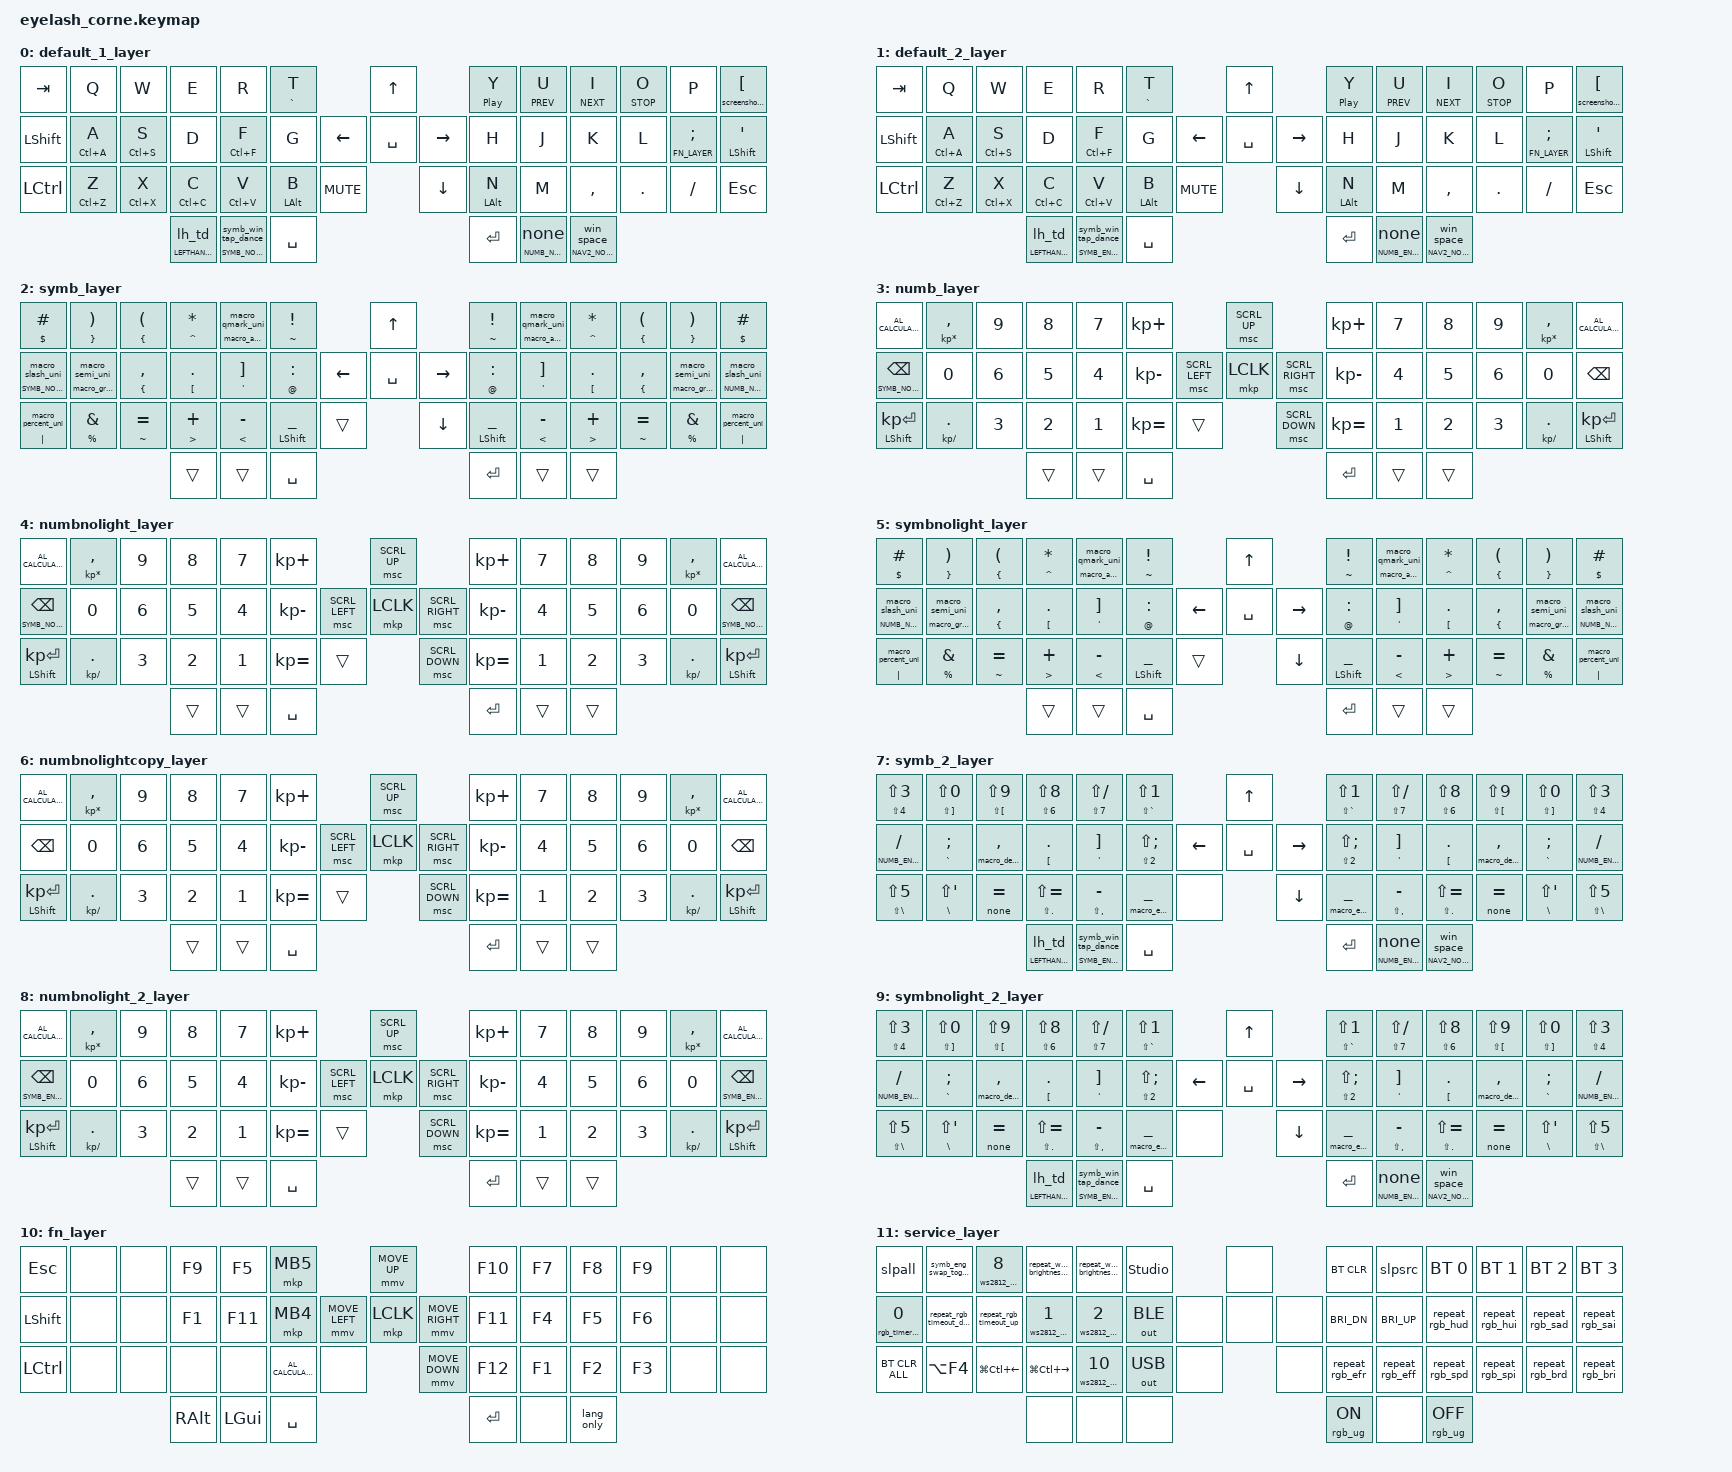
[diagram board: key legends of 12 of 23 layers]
#define ZMK_POINTING_DEFAULT_MOVE_VAL 1200
#define ZMK_POINTING_DEFAULT_SCRL_VAL 25
#include <input/processors.dtsi>
#include <zephyr/dt-bindings/input/input-event-codes.h>
#include <behaviors.dtsi>
#include <behaviors/ws2812_widget.dtsi>
#include <behaviors/ws2812_layer_sync.dtsi>
#include <behaviors/ws2812_activity_sync.dtsi>
#include <dt-bindings/zmk/bt.h>
#include <dt-bindings/zmk/keys.h>
#include <dt-bindings/zmk/outputs.h>
#include <dt-bindings/zmk/pointing.h>
#include <dt-bindings/zmk/rgb.h>
#include <behaviors/rgb_timer.dtsi>
#include <behaviors/sleep_source.dtsi>
#include <behaviors/sleep_all.dtsi>

#define BASE_LAYER                    0   // default_layer -> default_1_layer
#define KP_MODE_LAYER                 1   // kp_mode_layer -> default_2_layer
#define SYMB_LAYER                    2
#define NUMB_LAYER                    3
#define NUMB_NOLIGHT_LAYER            4
#define SYMB_NOLIGHT_LAYER            5
#define NUMB_NOLIGHT_COPY_LAYER       6
#define SYMB_ENG_LAYER                7   // symb_layer_eng -> symb_2_layer
#define NUMB_ENG_NOLIGHT_LAYER        8   // numbnolight_eng_layer -> numbnolight_2_layer
#define SYMB_ENG_NOLIGHT_LAYER        9   // symbnolight_eng_layer -> symbnolight_2_layer
#define FN_LAYER                      10
#define SERVICE_LAYER                 11
#define NAV1_LAYER                    12  // nav1_layer    -> nav_1_layer
#define NAV2_LAYER                    13  // nav2_layer    -> nav_2_layer
#define NAV2_NOLIGHT_LAYER            14
#define NAV3_LAYER                    15  // nav3_layer    -> nav_3_layer
#define GAMING1_LAYER                 16  // gaming1_layer -> gaming_1_layer
#define GAMING2_LAYER                 17  // gaming2_layer -> gaming_2_layer
#define GAMING3_LAYER                 18  // gaming3_layer -> gaming_3_layer
#define SPEEDTYPE_LAYER               19  // speedtype     -> speedtype_layer
#define LEFTHAND_LAYER                20
#define LEFTHAND_NOLIGHT_LAYER        21
#define NUMB_ENG_NOLIGHT_COPY_LAYER   22  // numbnolight_eng_copy_layer -> numbnolight_copy_2_layer

// --- НАСТРОЙКИ ОБОРУДОВАНИЯ И ПЕРИФЕРИИ ---
// Количество адресных светодиодов WS2812 на одной половине сплит-клавиатуры
&led_strip {
	chain-length = <21>;
};

// Базовые параметры скорости перемещения курсора мыши и скролла:
// Увеличение чувствительности курсора (x2) и стандартный скролл (x1)
&mmv_input_listener { input-processors = <&zip_xy_scaler 2 1>; };
&msc_input_listener { input-processors = <&zip_scroll_scaler 1 1>; };

// Настройки поведения прокрутки мыши (колесо):
// Мгновенный отклик, нулевая задержка и отсутствие кривой ускорения
&msc {
	acceleration-exponent = <0>;
	time-to-max-speed-ms = <0>;
	delay-ms = <0>;
};

// Настройки поведения курсора мыши (эмуляция перемещения указателя):
// Плавный разгон до максимальной скорости за 500 мс, линейное ускорение;
// trigger-period-ms = 16 задаёт период повторной генерации движения.
&mmv {
	time-to-max-speed-ms = <500>;
	acceleration-exponent = <1>;
	trigger-period-ms = <16>;
};

/ {
	chosen {
		zmk,ws2812-widget = &led_strip;
	};

	// Soft Off: разрешить пробуждение любой клавишей матрицы.
	// kscan0 уже имеет wakeup-source в eyelash_corne.dtsi.
	soft_off_wakers {
		compatible = "zmk,soft-off-wakeup-sources";
		wakeup-sources = <&kscan0>;
	};

	// --- ПОВЕДЕНИЯ КЛАВИШ (BEHAVIORS) ---
	behaviors {
		// ============================================================
		// CAPS LOCK + ИНДИКАЦИЯ НА LED 5,6 (БЕЗ СЛОЯ-ФЛАГА)
		// ============================================================
		// caps_toggle отправляет обычный HID Caps Lock (&kp CAPS).
		// Сам keymap не хранит отдельный слой/флаг для состояния Caps.
		//
		// На левой половине widget.c, при CONFIG_ZMK_HID_INDICATORS=y,
		// слушает событие zmk_hid_indicators_changed и берёт РЕАЛЬНОЕ состояние Caps Lock из HID-indicator report хоста.
		//
		// Поэтому двойное срабатывание R+T через combo_rt_caps_td
		// переключает Caps, а LED 5,6 отражают подтверждённое хостом состояние.
		// ============================================================

		// Макрос отправки Caps Lock. Подсветкой непосредственно он не управляет.
		caps_toggle: caps_toggle {
			compatible = "zmk,behavior-macro";
			#binding-cells = <0>;
			wait-ms = <20>;   // Параметр задержки между действиями макроса
			tap-ms = <20>;    // Длительность tap-события макроса
			bindings = <&kp CAPS>;
		};

		// ============================================================
		// МАКРОСЫ ws2812_eff_*
		// ============================================================
		// Справка по параметрам текущего zmk-ws2812-driver/main:
		//   0 = ручная индикация слоя;
		//   1 = индикация батареи локальной половины;
		//   2 = переключение временных WS2812-индикаций;
		//   3 = включение временных индикаций;
		//   4 = выключение временных индикаций;
		//   5 = индикация батареи обеих половин;
		//   6 = уменьшение яркости виджетов WS2812 на 10%;
		//   7 = увеличение яркости виджетов WS2812 на 10%;
		//   8 = сброс яркости виджетов WS2812 на 50%;
		//   9 = оранжевая индикация слоя.
		// ============================================================

		// Историческое имя "next" сохранено; &ws2812_wdg 6 уменьшает яркость виджетов.
		ws2812_eff_next: ws2812_eff_next {
			compatible = "zmk,behavior-macro";
			#binding-cells = <0>;
			wait-ms = <0>;
			tap-ms = <0>;
			bindings = <&ws2812_wdg 6>;
		};

		// Историческое имя "prev" сохранено; &ws2812_wdg 7 увеличивает яркость виджетов.
		ws2812_eff_prev: ws2812_eff_prev {
			compatible = "zmk,behavior-macro";
			#binding-cells = <0>;
			wait-ms = <0>;
			tap-ms = <0>;
			bindings = <&ws2812_wdg 7>;
		};

		// Историческое имя "off" сохранено; &ws2812_wdg 8 сбрасывает яркость виджетов на 50%.
		ws2812_eff_off: ws2812_eff_off {
			compatible = "zmk,behavior-macro";
			#binding-cells = <0>;
			wait-ms = <0>;
			tap-ms = <0>;
			bindings = <&ws2812_wdg 8>;
		};

		// Переименовано, чтобы не конфликтовать с возможным rgb_timer из include.
		rgb_timer_custom: rgbtimer_custom {
			compatible = "zmk,behavior-rgb-timer";
			#binding-cells = <1>;
		};

		rgb_timeout_up: rgb_timeout_up {
			compatible = "zmk,behavior-rgb-timeout";
			#binding-cells = <1>;
		};

		rgb_timeout_down: rgb_timeout_down {
			compatible = "zmk,behavior-rgb-timeout";
			#binding-cells = <1>;
		};

		// Автоповтор: действие сразу, повтор через 450 мс, затем каждые 200 мс.
		repeat_rgb_hud: repeat_rgb_hud {
			compatible = "zmk,behavior-auto-repeat";
			#binding-cells = <0>;
			bindings = <&rgb_ug RGB_HUD>;
			delay-ms = <450>;
			interval-ms = <200>;
		};

		// Автоповтор: действие сразу, повтор через 450 мс, затем каждые 200 мс.
		repeat_rgb_hui: repeat_rgb_hui {
			compatible = "zmk,behavior-auto-repeat";
			#binding-cells = <0>;
			bindings = <&rgb_ug RGB_HUI>;
			delay-ms = <450>;
			interval-ms = <200>;
		};

		// Автоповтор: действие сразу, повтор через 450 мс, затем каждые 200 мс.
		repeat_rgb_sad: repeat_rgb_sad {
			compatible = "zmk,behavior-auto-repeat";
			#binding-cells = <0>;
			bindings = <&rgb_ug RGB_SAD>;
			delay-ms = <450>;
			interval-ms = <200>;
		};

		// Автоповтор: действие сразу, повтор через 450 мс, затем каждые 200 мс.
		repeat_rgb_sai: repeat_rgb_sai {
			compatible = "zmk,behavior-auto-repeat";
			#binding-cells = <0>;
			bindings = <&rgb_ug RGB_SAI>;
			delay-ms = <450>;
			interval-ms = <200>;
		};

		// Автоповтор: действие сразу, повтор через 450 мс, затем каждые 200 мс.
		repeat_rgb_spd: repeat_rgb_spd {
			compatible = "zmk,behavior-auto-repeat";
			#binding-cells = <0>;
			bindings = <&rgb_ug RGB_SPD>;
			delay-ms = <450>;
			interval-ms = <200>;
		};

		// Автоповтор: действие сразу, повтор через 450 мс, затем каждые 200 мс.
		repeat_rgb_spi: repeat_rgb_spi {
			compatible = "zmk,behavior-auto-repeat";
			#binding-cells = <0>;
			bindings = <&rgb_ug RGB_SPI>;
			delay-ms = <450>;
			interval-ms = <200>;
		};

		// Автоповтор: действие сразу, повтор через 450 мс, затем каждые 200 мс.
		repeat_rgb_brd: repeat_rgb_brd {
			compatible = "zmk,behavior-auto-repeat";
			#binding-cells = <0>;
			bindings = <&rgb_ug RGB_BRD>;
			delay-ms = <450>;
			interval-ms = <200>;
		};

		// Автоповтор: действие сразу, повтор через 450 мс, затем каждые 200 мс.
		repeat_rgb_bri: repeat_rgb_bri {
			compatible = "zmk,behavior-auto-repeat";
			#binding-cells = <0>;
			bindings = <&rgb_ug RGB_BRI>;
			delay-ms = <450>;
			interval-ms = <200>;
		};
				// Автоповтор переключения на предыдущий RGB-эффект.
		repeat_rgb_efr: repeat_rgb_efr {
			compatible = "zmk,behavior-auto-repeat";
			#binding-cells = <0>;
			bindings = <&rgb_ug RGB_EFR>;
			delay-ms = <450>;
			interval-ms = <200>;
		};

		// Автоповтор переключения на следующий RGB-эффект.
		repeat_rgb_eff: repeat_rgb_eff {
			compatible = "zmk,behavior-auto-repeat";
			#binding-cells = <0>;
			bindings = <&rgb_ug RGB_EFF>;
			delay-ms = <450>;
			interval-ms = <200>;
		};

		// Автоповтор: действие сразу, повтор через 450 мс, затем каждые 200 мс.
		repeat_rgb_timeout_down: repeat_rgb_timeout_down {
			compatible = "zmk,behavior-auto-repeat";
			#binding-cells = <0>;
			bindings = <&rgb_timer_custom 2>;
			delay-ms = <450>;
			interval-ms = <200>;
		};

		// Автоповтор: действие сразу, повтор через 450 мс, затем каждые 200 мс.
		repeat_rgb_timeout_up: repeat_rgb_timeout_up {
			compatible = "zmk,behavior-auto-repeat";
			#binding-cells = <0>;
			bindings = <&rgb_timer_custom 1>;
			delay-ms = <450>;
			interval-ms = <200>;
		};

		// Автоповтор: действие сразу, повтор через 450 мс, затем каждые 200 мс.
		repeat_ws2812_brightness_down: repeat_ws2812_brightness_down {
			compatible = "zmk,behavior-auto-repeat";
			#binding-cells = <0>;
			bindings = <&ws2812_wdg 6>;
			delay-ms = <450>;
			interval-ms = <200>;
		};

		// Автоповтор: действие сразу, повтор через 450 мс, затем каждые 200 мс.
		repeat_ws2812_brightness_up: repeat_ws2812_brightness_up {
			compatible = "zmk,behavior-auto-repeat";
			#binding-cells = <0>;
			bindings = <&ws2812_wdg 7>;
			delay-ms = <450>;
			interval-ms = <200>;
		};

		// Вспомогательный макрос для одиночного срабатывания комбо R+T:
		// Быстро отправляет буквы R и T подряд без задержки
		macro_combo_rt: macro_combo_rt {
			compatible = "zmk,behavior-macro";
			#binding-cells = <0>;
			wait-ms = <0>;
			tap-ms = <0>;
			bindings = <&macro_tap &kp R>, <&macro_tap &kp T>;
		};

		// Tap Dance для комбо R+T:
		// 1 одновременное нажатие = вывод макроса R+T (просто буквы)
		// 2 одновременных нажатия (окно 450 мс) = переключение Caps + подсветка
		combo_rt_caps_td: combo_rt_caps_td {
			compatible = "zmk,behavior-tap-dance";
			#binding-cells = <0>;
			tapping-term-ms = <450>;
			bindings = <&macro_combo_rt>, <&caps_toggle>;
		};

		// ============================================================
		// КОНЕЦ БЛОКА CAPS LOCK ПОДСВЕТКИ
		// ============================================================

		// Макрос для точки через Alt+Code (046 на NumPad = точка)
		macro_dot_uni: macro_dot_uni {
			compatible = "zmk,behavior-macro";
			#binding-cells = <0>;
			wait-ms = <5>;
			tap-ms = <5>;
			bindings =
				<&macro_press &kp LALT>,
				<&macro_tap &kp KP_N0>,
				<&macro_tap &kp KP_N4>,
				<&macro_tap &kp KP_N6>,
				<&macro_release &kp LALT>;
		};

		// Макрос для запятой через Alt+Code (044 на NumPad = запятая)
		macro_comma_uni: macro_comma_uni {
			compatible = "zmk,behavior-macro";
			#binding-cells = <0>;
			wait-ms = <5>;
			tap-ms = <5>;
			bindings =
				<&macro_press &kp LALT>,
				<&macro_tap &kp KP_N0>,
				<&macro_tap &kp KP_N4>,
				<&macro_tap &kp KP_N4>,
				<&macro_release &kp LALT>;
		};

		// Знак вопроса через Alt+Code (063 на NumPad = ?)
		macro_qmark_uni: macro_qmark_uni {
			compatible = "zmk,behavior-macro";
			#binding-cells = <0>;
			wait-ms = <5>;
			tap-ms = <5>;
			bindings =
				<&macro_press &kp LALT>,
				<&macro_tap &kp KP_N0>,
				<&macro_tap &kp KP_N6>,
				<&macro_tap &kp KP_N3>,
				<&macro_release &kp LALT>;
		};

		// Двоеточие через Alt+Code (058 на NumPad = :)
		macro_colon_uni: macro_colon_uni {
			compatible = "zmk,behavior-macro";
			#binding-cells = <0>;
			wait-ms = <5>;
			tap-ms = <5>;
			bindings =
				<&macro_press &kp LALT>,
				<&macro_tap &kp KP_N0>,
				<&macro_tap &kp KP_N5>,
				<&macro_tap &kp KP_N8>,
				<&macro_release &kp LALT>;
		};

		// Точка с запятой через Alt+Code (059 на NumPad = ;)
		macro_semi_uni: macro_semi_uni {
			compatible = "zmk,behavior-macro";
			#binding-cells = <0>;
			wait-ms = <5>;
			tap-ms = <5>;
			bindings =
				<&macro_press &kp LALT>,
				<&macro_tap &kp KP_N0>,
				<&macro_tap &kp KP_N5>,
				<&macro_tap &kp KP_N9>,
				<&macro_release &kp LALT>;
		};

		// Слэш через Alt+Code (047 на NumPad = /)
		macro_slash_uni: macro_slash_uni {
			compatible = "zmk,behavior-macro";
			#binding-cells = <0>;
			wait-ms = <5>;
			tap-ms = <5>;
			bindings =
				<&macro_press &kp LALT>,
				<&macro_tap &kp KP_N0>,
				<&macro_tap &kp KP_N4>,
				<&macro_tap &kp KP_N7>,
				<&macro_release &kp LALT>;
		};

		// Обратный слэш через Alt+Code (092 на NumPad = \).
		macro_bslh_uni: macro_bslh_uni {
			compatible = "zmk,behavior-macro";
			#binding-cells = <0>;
			wait-ms = <5>;
			tap-ms = <5>;
			bindings =
				<&macro_press &kp LALT>,
				<&macro_tap &kp KP_N0>,
				<&macro_tap &kp KP_N9>,
				<&macro_tap &kp KP_N2>,
				<&macro_release &kp LALT>;
		};

		// @ через Alt+Code (064 = @)
		macro_at_uni: macro_at_uni {
			compatible = "zmk,behavior-macro";
			#binding-cells = <0>;
			wait-ms = <5>;
			tap-ms = <5>;
			bindings =
				<&macro_press &kp LALT>,
				<&macro_tap &kp KP_N0>,
				<&macro_tap &kp KP_N6>,
				<&macro_tap &kp KP_N4>,
				<&macro_release &kp LALT>;
		};

		// ' через Alt+Code (039 = ')
		macro_sqt_uni: macro_sqt_uni {
			compatible = "zmk,behavior-macro";
			#binding-cells = <0>;
			wait-ms = <5>;
			tap-ms = <5>;
			bindings =
				<&macro_press &kp LALT>,
				<&macro_tap &kp KP_N0>,
				<&macro_tap &kp KP_N3>,
				<&macro_tap &kp KP_N9>,
				<&macro_release &kp LALT>;
		};

		// } через Alt+Code (125 = })
		macro_rbrc_uni: macro_rbrc_uni {
			compatible = "zmk,behavior-macro";
			#binding-cells = <0>;
			wait-ms = <5>;
			tap-ms = <5>;
			bindings =
				<&macro_press &kp LALT>,
				<&macro_tap &kp KP_N1>,
				<&macro_tap &kp KP_N2>,
				<&macro_tap &kp KP_N5>,
				<&macro_release &kp LALT>;
		};

		// " однократно (без повтора при удержании)
		macro_dqt_once: macro_dqt_once {
			compatible = "zmk,behavior-macro";
			#binding-cells = <0>;
			wait-ms = <0>;
			tap-ms = <0>;
			bindings =
				<&macro_press &kp DQT>,
				<&macro_release &kp DQT>;
		};

		// Поведение для слоя Lefthand no-light: TAB через Alt+Tab
		alt_tab: alt_tab {
			compatible = "zmk,behavior-macro";
			#binding-cells = <0>;
			wait-ms = <0>;
			tap-ms = <20>;
			bindings =
				<&macro_press &kp LALT>,
				<&macro_tap &kp TAB>,
				<&macro_release &kp LALT>;
		};

		// ~ через Alt+Code (126 = ~)
		macro_tilde_uni: macro_tilde_uni {
			compatible = "zmk,behavior-macro";
			#binding-cells = <0>;
			wait-ms = <5>;
			tap-ms = <5>;
			bindings =
				<&macro_press &kp LALT>,
				<&macro_tap &kp KP_N0>,
				<&macro_tap &kp KP_N1>,
				<&macro_tap &kp KP_N2>,
				<&macro_tap &kp KP_N6>,
				<&macro_release &kp LALT>;
		};

		// | через Alt+Code (124 = |)
		macro_pipe_uni: macro_pipe_uni {
			compatible = "zmk,behavior-macro";
			#binding-cells = <0>;
			wait-ms = <5>;
			tap-ms = <5>;
			bindings =
				<&macro_press &kp LALT>,
				<&macro_tap &kp KP_N0>,
				<&macro_tap &kp KP_N1>,
				<&macro_tap &kp KP_N2>,
				<&macro_tap &kp KP_N4>,
				<&macro_release &kp LALT>;
		};

		// [ через Alt+Code (091 = [)
		macro_lbkt_uni: macro_lbkt_uni {
			compatible = "zmk,behavior-macro";
			#binding-cells = <0>;
			wait-ms = <5>;
			tap-ms = <5>;
			bindings =
				<&macro_press &kp LALT>,
				<&macro_tap &kp KP_N0>,
				<&macro_tap &kp KP_N9>,
				<&macro_tap &kp KP_N1>,
				<&macro_release &kp LALT>;
		};

		// { через Alt+Code (123 = {)
		macro_lbrc_uni: macro_lbrc_uni {
			compatible = "zmk,behavior-macro";
			#binding-cells = <0>;
			wait-ms = <5>;
			tap-ms = <5>;
			bindings =
				<&macro_press &kp LALT>,
				<&macro_tap &kp KP_N1>,
				<&macro_tap &kp KP_N2>,
				<&macro_tap &kp KP_N3>,
				<&macro_release &kp LALT>;
		};

		// $ через Alt+Code (036 = $)
		macro_dollar_uni: macro_dollar_uni {
			compatible = "zmk,behavior-macro";
			#binding-cells = <0>;
			wait-ms = <5>;
			tap-ms = <5>;
			bindings =
				<&macro_press &kp LALT>,
				<&macro_tap &kp KP_N0>,
				<&macro_tap &kp KP_N3>,
				<&macro_tap &kp KP_N6>,
				<&macro_release &kp LALT>;
		};

		// ` через Alt+Code (096 = `)
		macro_grave_uni: macro_grave_uni {
			compatible = "zmk,behavior-macro";
			#binding-cells = <0>;
			wait-ms = <5>;
			tap-ms = <5>;
			bindings =
				<&macro_press &kp LALT>,
				<&macro_tap &kp KP_N0>,
				<&macro_tap &kp KP_N9>,
				<&macro_tap &kp KP_N6>,
				<&macro_release &kp LALT>;
		};

		macro_tilde_direct: macro_tilde_direct {
			compatible = "zmk,behavior-macro";
			#binding-cells = <0>;
			wait-ms = <0>;
			tap-ms = <0>;
			bindings = <&kp LS(GRAVE)>;
		};

		// ° через Alt+Code (0176 = °)
		macro_degree_uni: macro_degree_uni {
			compatible = "zmk,behavior-macro";
			#binding-cells = <0>;
			wait-ms = <5>;
			tap-ms = <5>;
			bindings =
				<&macro_press &kp LALT>,
				<&macro_tap &kp KP_N0>,
				<&macro_tap &kp KP_N1>,
				<&macro_tap &kp KP_N7>,
				<&macro_tap &kp KP_N6>,
				<&macro_release &kp LALT>;
		};

		// — через Alt+Code (0151 = em dash)
		macro_emdash_uni: macro_emdash_uni {
			compatible = "zmk,behavior-macro";
			#binding-cells = <0>;
			wait-ms = <5>;
			tap-ms = <5>;
			bindings =
				<&macro_press &kp LALT>,
				<&macro_tap &kp KP_N0>,
				<&macro_tap &kp KP_N1>,
				<&macro_tap &kp KP_N5>,
				<&macro_tap &kp KP_N1>,
				<&macro_release &kp LALT>;
		};

		// & через Alt+Code (038 = &)
		macro_amp_uni: macro_amp_uni {
			compatible = "zmk,behavior-macro";
			#binding-cells = <0>;
			wait-ms = <5>;
			tap-ms = <5>;
			bindings =
				<&macro_press &kp LALT>,
				<&macro_tap &kp KP_N0>,
				<&macro_tap &kp KP_N3>,
				<&macro_tap &kp KP_N8>,
				<&macro_release &kp LALT>;
		};

		// ^ через Alt+Code (094 = ^)
		macro_caret_uni: macro_caret_uni {
			compatible = "zmk,behavior-macro";
			#binding-cells = <0>;
			wait-ms = <5>;
			tap-ms = <5>;
			bindings =
				<&macro_press &kp LALT>,
				<&macro_tap &kp KP_N0>,
				<&macro_tap &kp KP_N9>,
				<&macro_tap &kp KP_N4>,
				<&macro_release &kp LALT>;
		};

		// < через Alt+Code (060 = <)
		macro_lt_uni: macro_lt_uni {
			compatible = "zmk,behavior-macro";
			#binding-cells = <0>;
			wait-ms = <5>;
			tap-ms = <5>;
			bindings =
				<&macro_press &kp LALT>,
				<&macro_tap &kp KP_N0>,
				<&macro_tap &kp KP_N6>,
				<&macro_tap &kp KP_N0>,
				<&macro_release &kp LALT>;
		};

		// > через Alt+Code (062 = >)
		macro_gt_uni: macro_gt_uni {
			compatible = "zmk,behavior-macro";
			#binding-cells = <0>;
			wait-ms = <5>;
			tap-ms = <5>;
			bindings =
				<&macro_press &kp LALT>,
				<&macro_tap &kp KP_N0>,
				<&macro_tap &kp KP_N6>,
				<&macro_tap &kp KP_N2>,
				<&macro_release &kp LALT>;
		};

		// " через Alt+Code (034 = ")
		macro_dqt_uni: macro_dqt_uni {
			compatible = "zmk,behavior-macro";
			#binding-cells = <0>;
			wait-ms = <5>;
			tap-ms = <5>;
			bindings =
				<&macro_press &kp LALT>,
				<&macro_tap &kp KP_N0>,
				<&macro_tap &kp KP_N3>,
				<&macro_tap &kp KP_N4>,
				<&macro_release &kp LALT>;
		};

		// % через Alt+Code (037 = %)
		macro_percent_uni: macro_percent_uni {
			compatible = "zmk,behavior-macro";
			#binding-cells = <0>;
			wait-ms = <5>;
			tap-ms = <5>;
			bindings =
				<&macro_press &kp LALT>,
				<&macro_tap &kp KP_N0>,
				<&macro_tap &kp KP_N3>,
				<&macro_tap &kp KP_N7>,
				<&macro_release &kp LALT>;
		};

		// Hold-Tap symb_win_td (Левая клавиша большого пальца):
		// Удержание -> слой, переданный первым параметром.
		// В слое 0:      &symb_win_td SYMB_NOLIGHT_LAYER 0
		// В default_2:     &symb_win_td SYMB_ENG_NOLIGHT_LAYER 0
		// В циан-слоях:  &symb_win_td SYMB_ENG_NOLIGHT_LAYER 0
		// Одиночный тап -> ничего (none)
		// Двойной тап (окно 500 мс) -> Win (LGUI) через symb_win_tap_dance
		symb_win_td: symb_win_td {
			compatible = "zmk,behavior-hold-tap";
			#binding-cells = <2>;
			flavor = "tap-preferred";
			tapping-term-ms = <200>;
			quick-tap-ms = <300>;
			bindings = <&mo>, <&symb_win_tap_dance>;
		};

		// Вспомогательный Tap Dance для symb_win_td:
		// 1 тап = none (ничего), 2 тапа (окно 500 мс) = kp LGUI (Win)
		symb_win_tap_dance: symb_win_tap_dance {
			compatible = "zmk,behavior-tap-dance";
			#binding-cells = <0>;
			tapping-term-ms = <500>;
			bindings = <&none>, <&kp LGUI>;
		};

		// Hold-Tap thumb_num_sym_fn:
		// Удержание -> слой, переданный первым параметром.
		// В слое 0:      &thumb_num_sym_fn NUMB_NOLIGHT_LAYER 0
		// В default_2:     &thumb_num_sym_fn NUMB_ENG_NOLIGHT_LAYER 0
		// В циан-слоях:  &thumb_num_sym_fn NUMB_ENG_NOLIGHT_LAYER 0
		// Тап -> &none
		thumb_num_sym_fn: thumb_num_sym_fn {
			compatible = "zmk,behavior-hold-tap";
			#binding-cells = <2>;
			flavor = "tap-preferred";
			tapping-term-ms = <80>;
			bindings = <&mo>, <&none>;
		};

		// Speedtype -> NUMB_ENG_NOLIGHT без перестановки слоёв.
		// SPEEDTYPE_LAYER имеет больший номер, поэтому обычный &mo на нижний цифровой слой
		// был бы перекрыт активным Speedtype. Эти два behavior принудительно выключают/
		// включают SPEEDTYPE_LAYER, не меняя порядок существующих слоёв.
		layer_on: layer_on {
			compatible = "zmk,behavior-toggle-layer";
			#binding-cells = <1>;
			toggle-mode = "on";
		};

		layer_off: layer_off {
			compatible = "zmk,behavior-toggle-layer";
			#binding-cells = <1>;
			toggle-mode = "off";
		};

		// Пока speed_num_hold удерживается:
		// 1) выключаем фиксированный SPEEDTYPE_LAYER;
		// 2) временно включаем существующий NUMB_ENG_NOLIGHT_LAYER;
		// после отпускания выключаем цифры и возвращаем SPEEDTYPE_LAYER.
		speed_num_hold: speed_num_hold {
			compatible = "zmk,behavior-macro";
			#binding-cells = <0>;
			wait-ms = <0>;
			tap-ms = <0>;
			bindings =
				<&macro_tap &layer_off SPEEDTYPE_LAYER>,
				<&macro_press &mo NUMB_ENG_NOLIGHT_LAYER>,
				<&macro_pause_for_release>,
				<&macro_release &mo NUMB_ENG_NOLIGHT_LAYER>,
				<&macro_tap &layer_on SPEEDTYPE_LAYER>;
		};

		// Клавиша после Enter в SPEEDTYPE: tap = ничего, hold = цифровой слой.
		// Тайминг оставлен таким же, как у thumb_num_sym_fn.
		speed_num_ht: speed_num_ht {
			compatible = "zmk,behavior-hold-tap";
			#binding-cells = <2>;
			flavor = "tap-preferred";
			tapping-term-ms = <80>;
			bindings = <&speed_num_hold>, <&none>;
		};

		// Gaming -> NUMB_NOLIGHT_LAYER (Alt-ветка символов).
		// Во всех трёх gaming-слоях клавиша рядом с переключением языка:
		// tap = ничего, hold = NUMB_NOLIGHT_LAYER.
		// GAMING2/GAMING3 работают поверх GAMING1, поэтому для них временно
		// выключаются оба активных gaming-слоя, иначе слой 4 был бы перекрыт.
		gaming1_num_hold: gaming1_num_hold {
			compatible = "zmk,behavior-macro";
			#binding-cells = <0>;
			wait-ms = <0>;
			tap-ms = <0>;
			bindings =
				<&macro_tap &layer_off GAMING1_LAYER>,
				<&macro_press &mo NUMB_NOLIGHT_LAYER>,
				<&macro_pause_for_release>,
				<&macro_release &mo NUMB_NOLIGHT_LAYER>,
				<&macro_tap &layer_on GAMING1_LAYER>;
		};

		gaming1_num_ht: gaming1_num_ht {
			compatible = "zmk,behavior-hold-tap";
			#binding-cells = <2>;
			flavor = "tap-preferred";
			tapping-term-ms = <80>;
			bindings = <&gaming1_num_hold>, <&none>;
		};

		gaming2_num_hold: gaming2_num_hold {
			compatible = "zmk,behavior-macro";
			#binding-cells = <0>;
			wait-ms = <0>;
			tap-ms = <0>;
			bindings =
				<&macro_tap &layer_off GAMING2_LAYER>,
				<&macro_tap &layer_off GAMING1_LAYER>,
				<&macro_press &mo NUMB_NOLIGHT_LAYER>,
				<&macro_pause_for_release>,
				<&macro_release &mo NUMB_NOLIGHT_LAYER>,
				<&macro_tap &layer_on GAMING1_LAYER>,
				<&macro_tap &layer_on GAMING2_LAYER>;
		};

		gaming2_num_ht: gaming2_num_ht {
			compatible = "zmk,behavior-hold-tap";
			#binding-cells = <2>;
			flavor = "tap-preferred";
			tapping-term-ms = <80>;
			bindings = <&gaming2_num_hold>, <&none>;
		};

		gaming3_num_hold: gaming3_num_hold {
			compatible = "zmk,behavior-macro";
			#binding-cells = <0>;
			wait-ms = <0>;
			tap-ms = <0>;
			bindings =
				<&macro_tap &layer_off GAMING3_LAYER>,
				<&macro_tap &layer_off GAMING1_LAYER>,
				<&macro_press &mo NUMB_NOLIGHT_LAYER>,
				<&macro_pause_for_release>,
				<&macro_release &mo NUMB_NOLIGHT_LAYER>,
				<&macro_tap &layer_on GAMING1_LAYER>,
				<&macro_tap &layer_on GAMING3_LAYER>;
		};

		gaming3_num_ht: gaming3_num_ht {
			compatible = "zmk,behavior-hold-tap";
			#binding-cells = <2>;
			flavor = "tap-preferred";
			tapping-term-ms = <80>;
			bindings = <&gaming3_num_hold>, <&none>;
		};

		// LEFTHAND -> NUMB_NOLIGHT_LAYER (Alt-ветка символов).
		// Клавиша рядом с переключением языка: tap = ничего, hold = NUMB_NOLIGHT_LAYER.
		// На удержании текущий LEFTHAND-слой временно выключается, чтобы нижний слой 4 стал видимым.
		lefthand_num_hold: lefthand_num_hold {
			compatible = "zmk,behavior-macro";
			#binding-cells = <0>;
			wait-ms = <0>;
			tap-ms = <0>;
			bindings =
				<&macro_tap &layer_off LEFTHAND_LAYER>,
				<&macro_press &mo NUMB_NOLIGHT_LAYER>,
				<&macro_pause_for_release>,
				<&macro_release &mo NUMB_NOLIGHT_LAYER>,
				<&macro_tap &layer_on LEFTHAND_LAYER>;
		};

		lefthand_num_ht: lefthand_num_ht {
			compatible = "zmk,behavior-hold-tap";
			#binding-cells = <2>;
			flavor = "tap-preferred";
			tapping-term-ms = <80>;
			bindings = <&lefthand_num_hold>, <&none>;
		};

		lefthand_nolight_num_hold: lefthand_nolight_num_hold {
			compatible = "zmk,behavior-macro";
			#binding-cells = <0>;
			wait-ms = <0>;
			tap-ms = <0>;
			bindings =
				<&macro_tap &layer_off LEFTHAND_NOLIGHT_LAYER>,
				<&macro_press &mo NUMB_NOLIGHT_LAYER>,
				<&macro_pause_for_release>,
				<&macro_release &mo NUMB_NOLIGHT_LAYER>,
				<&macro_tap &layer_on LEFTHAND_NOLIGHT_LAYER>;
		};

		lefthand_nolight_num_ht: lefthand_nolight_num_ht {
			compatible = "zmk,behavior-hold-tap";
			#binding-cells = <2>;
			flavor = "tap-preferred";
			tapping-term-ms = <80>;
			bindings = <&lefthand_nolight_num_hold>, <&none>;
		};

		// Speedtype -> SYMB_LAYER без перестановки слоёв.
		// На удержании временно выключаем SPEEDTYPE_LAYER, включаем SYMB_LAYER,
		// а после отпускания возвращаем SPEEDTYPE_LAYER.
		speed_symb_hold: speed_symb_hold {
			compatible = "zmk,behavior-macro";
			#binding-cells = <0>;
			wait-ms = <0>;
			tap-ms = <0>;
			bindings =
				<&macro_tap &layer_off SPEEDTYPE_LAYER>,
				<&macro_press &mo SYMB_LAYER>,
				<&macro_pause_for_release>,
				<&macro_release &mo SYMB_LAYER>,
				<&macro_tap &layer_on SPEEDTYPE_LAYER>;
		};

		// Средняя клавиша большого пальца в SPEEDTYPE:
		// удержание = SYMB_LAYER, 1 тап = ничего, 2 тапа = Win (LGUI).
		speed_symb_win_ht: speed_symb_win_ht {
			compatible = "zmk,behavior-hold-tap";
			#binding-cells = <2>;
			flavor = "tap-preferred";
			tapping-term-ms = <200>;
			quick-tap-ms = <300>;
			bindings = <&speed_symb_hold>, <&symb_win_tap_dance>;
		};

		// Hold-Tap lefthand_ht (Крайняя левая клавиша большого пальца):
		// Удержание -> Слой LEFTHAND_NOLIGHT_LAYER
		// Одиночный тап -> ничего (через lh_td: 1 тап = none)
		// Двойной тап (окно 500 мс) -> &kp LALT (Left Alt)
		lefthand_ht: lefthand_ht {
			compatible = "zmk,behavior-hold-tap";
			#binding-cells = <2>;
			flavor = "tap-preferred";
			tapping-term-ms = <200>;
			quick-tap-ms = <300>;
			bindings = <&mo>, <&lh_td>;
		};

		// Вспомогательный Tap Dance для lefthand_ht:
		// 1 тап = none (ничего), 2 тапа (окно 500 мс) = kp LALT
		lh_td: lh_td {
			compatible = "zmk,behavior-tap-dance";
			#binding-cells = <0>;
			tapping-term-ms = <500>;
			bindings = <&none>, <&kp LALT>;
		};

		// Hold-Tap gaming_mo9_alt (Слой Gaming_1, левая клавиша большого пальца):
		// Удержание -> Временный Слой Gaming_3
		// Одиночный тап -> ничего (через gaming_mo9_td: 1 тап = none)
		// Двойной тап (окно 500 мс) -> kp LALT
		gaming_mo9_alt: gaming_mo9_alt {
			compatible = "zmk,behavior-hold-tap";
			#binding-cells = <2>;
			flavor = "tap-preferred";
			tapping-term-ms = <200>;
			quick-tap-ms = <300>;
			bindings = <&mo>, <&gaming_mo9_td>;
		};

		// Вспомогательный Tap Dance для gaming_mo9_alt:
		// 1 тап = none (ничего), 2 тапа (окно 500 мс) = kp LALT
		gaming_mo9_td: gaming_mo9_td {
			compatible = "zmk,behavior-tap-dance";
			#binding-cells = <0>;
			tapping-term-ms = <500>;
			bindings = <&none>, <&kp LALT>;
		};

		// Gaming_1: удержание -> Gaming_2
		// одиночный тап -> ничего
		// двойной тап -> Left Windows
		gaming_mo2_win: gaming_mo2_win {
    		compatible = "zmk,behavior-hold-tap";
    		#binding-cells = <2>;
    		flavor = "hold-preferred";
    		tapping-term-ms = <200>;
    		quick-tap-ms = <300>;
    		bindings = <&mo>, <&gaming_mo2_td>;
		};

		gaming_mo2_td: gaming_mo2_td {
    		compatible = "zmk,behavior-tap-dance";
    		#binding-cells = <0>;
    		tapping-term-ms = <500>;
    		bindings = <&none>, <&kp LGUI>;
		};

		// Hold-Tap gaming_shft_mo21 (LSHFT в слое gaming_2):
		// Удержание -> Временный Слой LEFTHAND_NOLIGHT_LAYER
		// Тап -> &kp LSHFT (обычный Shift)
		gaming_shft_mo21: gaming_shft_mo21 {
			compatible = "zmk,behavior-hold-tap";
			#binding-cells = <2>;
			flavor = "hold-preferred";
			tapping-term-ms = <200>;
			bindings = <&mo>, <&kp>;
		};

		// Hold-Tap lang_nav_2 (Клавиша переключения языка):
		// Удержание -> Временный Слой nav_2_NOLIGHT_LAYER
		// Одиночный тап -> Макрос Win+Space (смена языка в ОС)
		// Таймаут удержания: 220 мс, быстрое повторное нажатие: 150 мс
		lang_nav2: lang_nav2 {
			compatible = "zmk,behavior-hold-tap";
			#binding-cells = <2>;
			flavor = "tap-preferred";
			tapping-term-ms = <220>;
			quick-tap-ms = <150>;
			bindings = <&mo>, <&win_space>;
		};

		lang_only: lang_only {
    		compatible = "zmk,behavior-macro";
    		#binding-cells = <0>;
    		bindings = <&win_space>;
		};

		// Tap Dance nav_2_double_tap:
		// 1 тап = &trans; 2 тапа в пределах 300 мс -> &tog nav_2_LAYER
		nav2_double_tap: nav2_double_tap {
			compatible = "zmk,behavior-tap-dance";
			#binding-cells = <0>;
			tapping-term-ms = <300>;
			bindings = <&trans>, <&tog NAV2_LAYER>;
		};

		// Tap Dance speedtype_double_tap:
		// 1 тап = &trans; 2 тапа в пределах 300 мс -> &tog SPEEDTYPE_LAYER
		speedtype_double_tap: speedtype_double_tap {
			compatible = "zmk,behavior-tap-dance";
			#binding-cells = <0>;
			tapping-term-ms = <300>;
			bindings = <&trans>, <&tog SPEEDTYPE_LAYER>;
		};

		// Параметрический макрос kp_once:
		// Выполняет одиночное нажатие указанной клавиши (press + release за один вызов)
		// Используется в edit_ht чтобы Ctrl+A/S/F/Z/X/C/V не залипали
		kp_once: kp_once {
			compatible = "zmk,behavior-macro-one-param";
			#binding-cells = <1>;
			wait-ms = <0>;
			tap-ms = <0>;
			bindings =
				<&macro_param_1to1 &macro_press &kp 0>,
				<&macro_param_1to1 &macro_release &kp 0>;
		};

		// Hold-Tap (Клавиша T):
		// Тап -> Тильда ~ (через Grave, работает везде)
		// Удержание -> Тильда ~ (на случай удержания)
		// Hold отправляется ОДИН раз через kp_once (без автоповтора при удержании).
		t_yo_ht: t_yo_ht {
			compatible = "zmk,behavior-hold-tap";
			#binding-cells = <2>;
			flavor = "tap-preferred";
			tapping-term-ms = <220>;
			quick-tap-ms = <150>;
			// require-prior-idle-ms = <150>;
			bindings = <&kp_once>, <&kp>; // Оба слота принимают параметры
		};

		// Hold-Tap edit_ht (Клавиши редактирования левой руки: A, S, F, Z, X, C, V):
		// Тап -> Обычный символ
		// Удержание -> Сочетание Ctrl + клавиша (через макрос kp_once)
		edit_ht: edit_ht {
			compatible = "zmk,behavior-hold-tap";
			#binding-cells = <2>;
			flavor = "tap-preferred";
			tapping-term-ms = <220>;
			quick-tap-ms = <150>;
			require-prior-idle-ms = <150>;
			hold-trigger-key-positions = <26 27 28 29 30 31 32 33 34 35 38 39 40 41>;
			bindings = <&kp_once>, <&kp>;
		};

		// Hold-Tap media_ht (Медиа-клавиши верхнего ряда правой руки: Y, U, I, O):
		// Тап -> Буква (Y, U, I, O)
		// Удержание -> Управление плеером (Play/Pause, Prev, Next, Stop)
		media_ht: media_ht {
			compatible = "zmk,behavior-hold-tap";
			#binding-cells = <2>;
			flavor = "tap-preferred";
			tapping-term-ms = <220>;
			quick-tap-ms = <150>;
			require-prior-idle-ms = <150>;
			bindings = <&kp>, <&kp>;
		};

		// Hold-Tap n_alt_ht (Клавиша N):
		// Тап -> Символ N
		// Удержание -> Left Alt
		// Hold срабатывает ТОЛЬКО при касании позиций правой руки (26-35, 38-41)
		n_alt_ht: n_alt_ht {
			compatible = "zmk,behavior-hold-tap";
			#binding-cells = <2>;
			flavor = "tap-preferred";
			tapping-term-ms = <220>;
			quick-tap-ms = <150>;
			require-prior-idle-ms = <150>;
			hold-trigger-key-positions = <26 27 28 29 30 31 32 33 34 35 38 39 40 41>;
			bindings = <&kp>, <&kp>;
		};

		// Hold-Tap b_alt_ht (Клавиша B):
		// Тап -> Символ B
		// Удержание -> Left Alt
		// Hold срабатывает ТОЛЬКО при касании позиций правой руки (26-35, 38-41)
		b_alt_ht: b_alt_ht {
			compatible = "zmk,behavior-hold-tap";
			#binding-cells = <2>;
			flavor = "tap-preferred";
			tapping-term-ms = <220>;
			quick-tap-ms = <150>;
			require-prior-idle-ms = <150>;
			hold-trigger-key-positions = <26 27 28 29 30 31 32 33 34 35 38 39 40 41>;
			bindings = <&kp>, <&kp>;
		};

		// Универсальный Hold-Tap: hold = &mo <param1>, tap = &kp <param2>.
		// Используется, например:
		//   &bspc_to_layer_ht NUMB_NOLIGHT_LAYER SQT
		//   &bspc_to_layer_ht SYMB_ENG_NOLIGHT_LAYER FSLH
		bspc_to_layer_ht: bspc_to_layer_ht {
			compatible = "zmk,behavior-hold-tap";
			#binding-cells = <2>;
			flavor = "hold-preferred";
			tapping-term-ms = <200>;
			bindings = <&mo>, <&kp>;
		};

		// Универсальный Hold-Tap bspc_to_numb_ht:
		// hold = &mo <param1>, tap = &kp <param2>.
		// Используется для переходов между символьными и цифровыми слоями.
		bspc_to_numb_ht: bspc_to_numb_ht {
			compatible = "zmk,behavior-hold-tap";
			#binding-cells = <2>;
			flavor = "hold-preferred";
			tapping-term-ms = <200>;
			bindings = <&mo>, <&kp>;
		};

		// -------------------------------------------------------
		// behaviors для символьных раскладок (слои с Alt-code)
		// Используются зеркально на обеих сторонах символьных слоёв
		// -------------------------------------------------------

		// Hold-Tap excl_tilde_ht: тап=!, холд=макрос ~
		excl_tilde_ht: excl_tilde_ht {
			compatible = "zmk,behavior-hold-tap";
			#binding-cells = <2>;
			flavor = "hold-preferred";
			tapping-term-ms = <200>;
			bindings = <&macro_tilde_uni>, <&kp>;
		};

		// Hold-Tap qmark_dqt_ht: тап=? (Alt-code), холд=& (Alt-code)
		qmark_dqt_ht: qmark_dqt_ht {
			compatible = "zmk,behavior-hold-tap";
			#binding-cells = <2>;
			flavor = "hold-preferred";
			tapping-term-ms = <200>;
			bindings = <&macro_amp_uni>, <&macro_qmark_uni>;
		};

		// Hold-Tap astrk_caret_ht: тап=*, холд=^ (Alt-code)
		astrk_caret_ht: astrk_caret_ht {
			compatible = "zmk,behavior-hold-tap";
			#binding-cells = <2>;
			flavor = "hold-preferred";
			tapping-term-ms = <200>;
			bindings = <&macro_caret_uni>, <&kp>;
		};

		// Hold-Tap lpar_lbrc_ht: тап=(, холд=макрос {
		lpar_lbrc_ht: lpar_lbrc_ht {
			compatible = "zmk,behavior-hold-tap";
			#binding-cells = <2>;
			flavor = "hold-preferred";
			tapping-term-ms = <200>;
			bindings = <&macro_lbrc_uni>, <&kp>;
		};

		// Hold-Tap rpar_rbrc_ht: тап=), холд=макрос }
		rpar_rbrc_ht: rpar_rbrc_ht {
			compatible = "zmk,behavior-hold-tap";
			#binding-cells = <2>;
			flavor = "hold-preferred";
			tapping-term-ms = <200>;
			bindings = <&macro_rbrc_uni>, <&kp>;
		};

		// Hold-Tap hash_dollar_ht: тап=#, холд=макрос $
		hash_dollar_ht: hash_dollar_ht {
			compatible = "zmk,behavior-hold-tap";
			#binding-cells = <2>;
			flavor = "hold-preferred";
			tapping-term-ms = <200>;
			bindings = <&macro_dollar_uni>, <&kp>;
		};

		// Hold-Tap colon_at_ht: тап=: (Alt-code), холд=@ (Alt-code)
		colon_at_ht: colon_at_ht {
			compatible = "zmk,behavior-hold-tap";
			#binding-cells = <2>;
			flavor = "hold-preferred";
			tapping-term-ms = <200>;
			bindings = <&macro_at_uni>, <&macro_colon_uni>;
		};

		// Hold-Tap rbkt_sqt_ht: тап=] (kp), холд=' (Alt-code)
		rbkt_sqt_ht: rbkt_sqt_ht {
			compatible = "zmk,behavior-hold-tap";
			#binding-cells = <2>;
			flavor = "hold-preferred";
			tapping-term-ms = <200>;
			bindings = <&macro_sqt_uni>, <&kp>;
		};

		// Hold-Tap dot_lbkt_ht: тап=. (Alt-code), холд=макрос [
		dot_lbkt_ht: dot_lbkt_ht {
			compatible = "zmk,behavior-hold-tap";
			#binding-cells = <2>;
			flavor = "hold-preferred";
			tapping-term-ms = <200>;
			bindings = <&macro_lbkt_uni>, <&macro_dot_uni>;
		};

		// Hold-Tap comma_lbrc_ht: тап=, (Alt-code), холд=макрос °
		comma_lbrc_ht: comma_lbrc_ht {
			compatible = "zmk,behavior-hold-tap";
			#binding-cells = <2>;
			flavor = "hold-preferred";
			tapping-term-ms = <200>;
			bindings = <&macro_degree_uni>, <&macro_comma_uni>;
		};

		// Hold-Tap semi_rbrc_ht: тап=; (Alt-code), холд=макрос `
		semi_rbrc_ht: semi_rbrc_ht {
			compatible = "zmk,behavior-hold-tap";
			#binding-cells = <2>;
			flavor = "hold-preferred";
			tapping-term-ms = <200>;
			bindings = <&macro_grave_uni>, <&macro_semi_uni>;
		};

		// Hold-Tap slash_bslh_ht: тап=/ (Alt-code), холд=\
		// Крайний правый столбец строки 2
		slash_bslh_ht: slash_bslh_ht {
			compatible = "zmk,behavior-hold-tap";
			#binding-cells = <2>;
			flavor = "hold-preferred";
			tapping-term-ms = <200>;
			bindings = <&kp>, <&macro_slash_uni>;
		};

		// Hold-Tap slash_to_numb_ht:
		// Тап -> / через Alt-code; hold -> &mo <param1>.
		// Целевой слой задаётся отдельно на каждой клавише.
		slash_to_numb_ht: slash_to_numb_ht {
			compatible = "zmk,behavior-hold-tap";
			#binding-cells = <2>;
			flavor = "hold-preferred";
			tapping-term-ms = <200>;
			bindings = <&mo>, <&macro_slash_uni>;
		};

		// Hold-Tap under_lshft_ht: тап=_, холд=макрос — (em dash)
		under_lshft_ht: under_lshft_ht {
			compatible = "zmk,behavior-hold-tap";
			#binding-cells = <2>;
			flavor = "hold-preferred";
			tapping-term-ms = <200>;
			bindings = <&macro_emdash_uni>, <&kp>;
		};

		// Hold-Tap minus_lt_ht: тап=-, холд=< (Alt-code)
		minus_lt_ht: minus_lt_ht {
			compatible = "zmk,behavior-hold-tap";
			#binding-cells = <2>;
			flavor = "hold-preferred";
			tapping-term-ms = <200>;
			bindings = <&macro_lt_uni>, <&kp>;
		};

		// Hold-Tap plus_gt_ht: тап=+, холд=> (Alt-code)
		plus_gt_ht: plus_gt_ht {
			compatible = "zmk,behavior-hold-tap";
			#binding-cells = <2>;
			flavor = "hold-preferred";
			tapping-term-ms = <200>;
			bindings = <&macro_gt_uni>, <&kp>;
		};

		// Hold-Tap equal_tilde_ht: тап==, холд нет
		equal_tilde_ht: equal_tilde_ht {
			compatible = "zmk,behavior-hold-tap";
			#binding-cells = <2>;
			flavor = "hold-preferred";
			tapping-term-ms = <200>;
			bindings = <&none>, <&kp>;
		};

		// Hold-Tap percent_amp_ht: hold=\ (Alt-code), tap=" (Alt-code).
		percent_amp_ht: percent_amp_ht {
			compatible = "zmk,behavior-hold-tap";
			#binding-cells = <2>;
			flavor = "hold-preferred";
			tapping-term-ms = <200>;
			bindings = <&macro_bslh_uni>, <&macro_dqt_uni>;
		};

		// Hold-Tap dqt_pipe_ht: тап=% (Alt-code), холд=| (Alt-code)
		// Крайняя левая и правая клавиши строки 3 в символьных слоях
		dqt_pipe_ht: dqt_pipe_ht {
			compatible = "zmk,behavior-hold-tap";
			#binding-cells = <2>;
			flavor = "hold-preferred";
			tapping-term-ms = <200>;
			bindings = <&macro_pipe_uni>, <&macro_percent_uni>;
		};

		// Hold-Tap semi_fn_ht (Клавиша точки с запятой):
		// Тап -> Символ ; (точка с запятой)
		// Удержание -> Переход на Слой FN_LAYER
		// Hold срабатывает ТОЛЬКО при касании позиций правой руки (26-35, 38-41)
		semi_fn_ht: semi_fn_ht {
			compatible = "zmk,behavior-hold-tap";
			#binding-cells = <2>;
			flavor = "balanced";
			tapping-term-ms = <250>;
			hold-trigger-key-positions = <26 27 28 29 30 31 32 33 34 35 38 39 40 41>;
			bindings = <&mo>, <&kp>;
		};

		// Макрос screenshot_win_shift_s:
		// Эмулирует нажатие комбинации Win + Shift + S для создания скриншота в Windows
		screenshot_win_shift_s: screenshot_win_shift_s {
			compatible = "zmk,behavior-macro";
			#binding-cells = <0>;
			wait-ms = <0>;
			tap-ms = <0>;
			bindings =
				<&macro_press &kp LGUI>,
				<&macro_press &kp LSHIFT>,
				<&macro_tap &kp S>,
				<&macro_release &kp LSHIFT>,
				<&macro_release &kp LGUI>;
		};

		// Hold-Tap lbkt_screenshot (Клавиша '['):
		// Тап -> Символ открывающей квадратной скобки '['
		// Удержание -> Запуск макроса скриншота (Win + Shift + S)
		lbkt_screenshot: lbkt_screenshot {
			compatible = "zmk,behavior-hold-tap";
			#binding-cells = <2>;
			flavor = "tap-preferred";
			tapping-term-ms = <300>;
			quick-tap-ms = <200>;
			bindings = <&screenshot_win_shift_s>, <&kp>;
		};

		// Макрос win_space:
		// Быстрое последовательное нажатие Win + Space для переключения языка ввода
		win_space: win_space {
			compatible = "zmk,behavior-macro";
			#binding-cells = <0>;
			wait-ms = <0>;
			tap-ms = <0>;
			bindings =
				<&macro_press &kp LGUI>,
				<&macro_tap &kp SPACE>,
				<&macro_release &kp LGUI>;
		};

		// Макрос tog13_on:
		// Выполняет &tog LEFTHAND_LAYER и затем &ws2812_lsync 1.
		// В текущем layer-sync драйвере param1=1 означает временную индикацию "layer ON";
		// это НЕ отдельный постоянный RGB-профиль и не выбор underglow-эффекта.
		tog13_on: tog13_on {
			compatible = "zmk,behavior-macro";
			#binding-cells = <0>;
			wait-ms = <0>;
			tap-ms = <0>;
			bindings = <&tog LEFTHAND_LAYER>, <&ws2812_lsync 1>;
		};

		// Макрос tog13_off:
		// Выполняет &tog LEFTHAND_LAYER и затем &ws2812_lsync 0.
		// В текущем layer-sync драйвере param1=0 означает временную индикацию "layer OFF";
		// после неё widget.c восстанавливает статическое состояние/underglow.
		tog13_off: tog13_off {
			compatible = "zmk,behavior-macro";
			#binding-cells = <0>;
			wait-ms = <0>;
			tap-ms = <0>;
			bindings = <&tog LEFTHAND_LAYER>, <&ws2812_lsync 0>;
		};

		// Tap Dance tog13_on_td:
		// 1 тап = &trans, двойной тап -> tog13_on: toggle слоя Lefthand + временная ON-индикация
		tog13_on_td: tog13_on_td {
			compatible = "zmk,behavior-tap-dance";
			#binding-cells = <0>;
			tapping-term-ms = <300>;
			bindings = <&trans>, <&tog13_on>;
		};

		// Tap Dance tog13_off_td:
		// 1 тап = &trans, двойной тап -> tog13_off: toggle слоя Lefthand + временная OFF-индикация
		tog13_off_td: tog13_off_td {
			compatible = "zmk,behavior-tap-dance";
			#binding-cells = <0>;
			tapping-term-ms = <300>;
			bindings = <&trans>, <&tog13_off>;
		};

		// Tap Dance thumb_e_numb_td:
		// Используется в комбо: левый большой палец (pos 43) + G (pos 18).
		// Второе срабатывание переключает persistent слой NUMB_LAYER.
		thumb_e_numb_td: thumb_e_numb_td {
			compatible = "zmk,behavior-tap-dance";
			#binding-cells = <0>;
			tapping-term-ms = <300>;
			bindings = <&none>, <&tog NUMB_LAYER>;
		};

		// Tap Dance thumb_e_numb_eng_td (слой 1 / default_2):
		// Второе срабатывание переключает фиксированный английский слой NUMB_ENG_NOLIGHT_LAYER.
		thumb_e_numb_eng_td: thumb_e_numb_eng_td {
			compatible = "zmk,behavior-tap-dance";
			#binding-cells = <0>;
			tapping-term-ms = <300>;
			bindings = <&none>, <&tog NUMB_ENG_NOLIGHT_LAYER>;
		};

		// Tap Dance thumb_i_symb_nolight_td (слой 0 / BASE):
		// Второе срабатывание переключает фиксированный слой SYMB_NOLIGHT_LAYER.
		// Оставлен на случай, если захочешь вернуть тогл no-light слоя.
		thumb_i_symb_nolight_td: thumb_i_symb_nolight_td {
			compatible = "zmk,behavior-tap-dance";
			#binding-cells = <0>;
			tapping-term-ms = <300>;
			bindings = <&none>, <&tog SYMB_NOLIGHT_LAYER>;
		};

		// Tap Dance thumb_i_symb_td:
		// 1 тап = none (ничего), двойной тап -> Переключение persistent слоя SYMB_LAYER (символы Alt)
		// Используется в комбо: H (pos 22) + правый большой палец (pos 46).
		thumb_i_symb_td: thumb_i_symb_td {
			compatible = "zmk,behavior-tap-dance";
			#binding-cells = <0>;
			tapping-term-ms = <300>;
			bindings = <&none>, <&tog SYMB_LAYER>;
		};

		// Tap Dance для default_2 / English persistent:
		// 1 тап = none, двойной тап -> &tog SYMB_ENG_LAYER
		// Это и есть вход/выход в постоянный циановый английский символьный слой.
		thumb_i_symb_eng_td: thumb_i_symb_eng_td {
			compatible = "zmk,behavior-tap-dance";
			#binding-cells = <0>;
			tapping-term-ms = <300>;
			bindings = <&none>, <&tog SYMB_ENG_LAYER>;
		};

		// МАКРОС ПЕРЕХОДА НА СЛОЙ 0 + РУЧНАЯ WS2812-ИНДИКАЦИЯ
		reset_l0_green_flash: reset_l0_green_flash {
			compatible = "zmk,behavior-macro";
			#binding-cells = <0>;
			wait-ms = <20>;
			tap-ms = <20>;
			bindings =
				<&to BASE_LAYER>,
				<&ws2812_wdg 0>;
		};

		// МАКРОС ПЕРЕХОДА НА default_2 + РУЧНАЯ WS2812-ИНДИКАЦИЯ (оранжевая)
		// Принудительно включаем Android-режим, а не toggle.
		reset_kp_mode_green_flash: reset_kp_mode_green_flash {
			compatible = "zmk,behavior-macro";
			#binding-cells = <0>;
			wait-ms = <20>;
			tap-ms = <20>;
			bindings =
				<&to KP_MODE_LAYER>,
				<&ws2812_wdg 9>;
		};

		// Hold-Tap div_lshft_ht: тап=DIVIDE, холд=Left Shift
		// Используется в numb-слоях
		div_lshft_ht: div_lshft_ht {
			compatible = "zmk,behavior-hold-tap";
			#binding-cells = <2>;
			flavor = "hold-preferred";
			tapping-term-ms = <200>;
			bindings = <&kp>, <&kp>;
		};

		// Hold-Tap div_dot_ht: тап=. (Alt-code), холд=KP_DIVIDE
		div_dot_ht: div_dot_ht {
			compatible = "zmk,behavior-hold-tap";
			#binding-cells = <2>;
			flavor = "hold-preferred";
			tapping-term-ms = <200>;
			bindings = <&kp>, <&macro_dot_uni>;
		};

		// Hold-Tap mul_comma_ht: тап=, (Alt-code), холд=KP_MULTIPLY
		mul_comma_ht: mul_comma_ht {
			compatible = "zmk,behavior-hold-tap";
			#binding-cells = <2>;
			flavor = "hold-preferred";
			tapping-term-ms = <200>;
			bindings = <&kp>, <&macro_comma_uni>;
		};

		// ============================================================
		// Английские символьные hold-tap
		// ============================================================

		// Универсальный hold-tap для английских символов:
		// hold = &kp <param1>
		// tap  = &kp <param2>
		eng_ht: eng_ht {
			compatible = "zmk,behavior-hold-tap";
			#binding-cells = <2>;
			flavor = "hold-preferred";
			tapping-term-ms = <200>;
			bindings = <&kp>, <&kp>;
		};

		// Английские символьные слои 7 и 9:
		// hold = одиночный tap указанного символа через kp_once (без автоповтора)
		// tap  = обычный &kp <param2>
		eng_sym_ht: eng_sym_ht {
			compatible = "zmk,behavior-hold-tap";
			#binding-cells = <2>;
			flavor = "hold-preferred";
			tapping-term-ms = <200>;
			bindings = <&kp_once>, <&kp>;
		};

		// Универсальный hold-tap:
		// hold = none
		// tap  = &kp <param2>
		eng_ht_none_kp: eng_ht_none_kp {
			compatible = "zmk,behavior-hold-tap";
			#binding-cells = <2>;
			flavor = "hold-preferred";
			tapping-term-ms = <200>;
			bindings = <&none>, <&kp>;
		};

		// Alt-code hold (для символа нет кейкода без Alt). Используется в слоях 7 и 9.
		// Hold = ° через Alt-code, tap = обычный &kp <param2>
		eng_comma_degree_ht: eng_comma_degree_ht {
			compatible = "zmk,behavior-hold-tap";
			#binding-cells = <2>;
			flavor = "hold-preferred";
			tapping-term-ms = <200>;
			bindings = <&macro_degree_uni>, <&kp>;
		};

		// Alt-code hold (для символа нет кейкода без Alt). Используется в слоях 7 и 9.
		// Hold = — через Alt-code, tap = обычный &kp <param2>
		eng_under_emdash_ht: eng_under_emdash_ht {
			compatible = "zmk,behavior-hold-tap";
			#binding-cells = <2>;
			flavor = "hold-preferred";
			tapping-term-ms = <200>;
			bindings = <&macro_emdash_uni>, <&kp>;
		};

		// Кнопка переключения default_2:
		// Одно нажатие — включить слой 1 поверх 0.
		// Повторное нажатие — выключить слой 1.
		// Слой 1 является копией слоя 0 и переводит
		// большие пальцы на английские слои без Alt.
		symb_eng_swap_toggle: symb_eng_swap_toggle {
			compatible = "zmk,behavior-macro";
			#binding-cells = <0>;
			wait-ms = <0>;
			tap-ms = <0>;
			bindings = <&tog KP_MODE_LAYER>;
		};
	};

	// --- КОМБИНАЦИИ КЛАВИШ (COMBOS) ---
	combos {
		compatible = "zmk,combos";

		// Комбо R + T (позиции 4, 5), активно на базовых печатных слоях.
				combo_rt_caps {
			timeout-ms = <150>;
			require-prior-idle-ms = <150>;
			key-positions = <4 5>;
			bindings = <&combo_rt_caps_td>;
			layers = <
				BASE_LAYER
				KP_MODE_LAYER
				SPEEDTYPE_LAYER
			>;
		};

		// Комбо W + E + R + T (Клавиши 2, 3, 4, 5)
		// Включение / выключение игрового режима (gaming_1).
		combo_wert_gaming_toggle {
			timeout-ms = <100>;
			require-prior-idle-ms = <250>;
			key-positions = <2 3 4 5>;
			bindings = <&tog GAMING1_LAYER>;
			layers = <
				BASE_LAYER
				KP_MODE_LAYER
				SYMB_LAYER
				NUMB_LAYER
				SYMB_ENG_LAYER
				NAV2_LAYER
				GAMING1_LAYER
				SPEEDTYPE_LAYER
				LEFTHAND_LAYER
			>;
		};

		// Комбо Q + W (позиции 1, 2):
		// На BASE/default_2 вызывает tog13_on_td; двойное срабатывание tap-dance
		// делает toggle слоя Lefthand и временную WS2812 ON-индикацию.
		combo_qw_tog13_on {
			timeout-ms = <80>;
			require-prior-idle-ms = <150>;
			key-positions = <1 2>;
			bindings = <&tog13_on_td>;
			layers = <BASE_LAYER KP_MODE_LAYER>;
		};

		// Комбо Tab + Q:
		// При одновременном нажатии Tab и Q отправляется Esc
		combo_tab_q_esc {
			timeout-ms = <50>;
			require-prior-idle-ms = <100>;
			key-positions = <0 1>;
			bindings = <&kp ESC>;
			layers = <
				BASE_LAYER
				KP_MODE_LAYER
				NAV2_LAYER
				NAV2_NOLIGHT_LAYER
				GAMING1_LAYER
				SPEEDTYPE_LAYER
				LEFTHAND_LAYER
				LEFTHAND_NOLIGHT_LAYER
				SYMB_LAYER
                SYMB_NOLIGHT_LAYER
				NUMB_LAYER
                NUMB_NOLIGHT_LAYER
				SYMB_ENG_LAYER
                NUMB_NOLIGHT_COPY_LAYER
                NUMB_ENG_NOLIGHT_LAYER
                SYMB_ENG_NOLIGHT_LAYER
                NUMB_ENG_NOLIGHT_COPY_LAYER
			>;
		};

		// Комбо Q + W (позиции 1, 2):
		// На слое Lefthand вызывает tog13_off_td; двойное срабатывание tap-dance
		// делает toggle слоя Lefthand и временную WS2812 OFF-индикацию.
		combo_qw_tog13_off {
			timeout-ms = <80>;
			require-prior-idle-ms = <150>;
			key-positions = <1 2>;
			bindings = <&tog13_off_td>;
			layers = <LEFTHAND_LAYER>;
		};

		// Комбо E + R:
		// Временная активация nav_3
		combo_er_nav3 {
			timeout-ms = <150>;
			require-prior-idle-ms = <150>;
			key-positions = <3 4>;
			bindings = <&mo NAV3_LAYER>;
			layers = <
				BASE_LAYER
				KP_MODE_LAYER
				SPEEDTYPE_LAYER
			>;
		};

		// Комбо позиций 27 + 41:
		// Вызывает speedtype_double_tap; второе срабатывание tap-dance
		// переключает фиксированный слой Speedtype.
		// ВАЖНО: убрано с символьных слоёв, чтобы не конфликтовать с hold на цифры.
		combo_sqt_esc_speedtype {
			timeout-ms = <80>;
			require-prior-idle-ms = <150>;
			key-positions = <27 41>;
			bindings = <&speedtype_double_tap>;
			layers = <
				BASE_LAYER
				KP_MODE_LAYER
				SPEEDTYPE_LAYER
				GAMING1_LAYER
			>;
		};

		// Комбо D + F:
		// Временная активация nav_1
		combo_fd_nav {
			timeout-ms = <50>;
			require-prior-idle-ms = <100>;
			key-positions = <16 17>;
			bindings = <&mo NAV1_LAYER>;
			layers = <
				BASE_LAYER
				KP_MODE_LAYER
				SPEEDTYPE_LAYER
			>;
		};

		// Комбо двух нижних левых клавиш (Клавиши 42, 43):
		// Временная активация Service слоя: Bluetooth, USB/BLE output, RGB, ZMK Studio.
		combo_service {
			timeout-ms = <50>;
			require-prior-idle-ms = <100>;
			key-positions = <42 43>;
			bindings = <&mo SERVICE_LAYER>;
			layers = <
				BASE_LAYER
				KP_MODE_LAYER
                SPEEDTYPE_LAYER
			>;
		};

		// Комбо Y + U (позиции 7, 8):
		// Вызывает nav_2_double_tap; второе срабатывание tap-dance
		// переключает фиксированный слой nav_2
		combo_yu_nav2_double_tap {
			timeout-ms = <80>;
			require-prior-idle-ms = <150>;
			key-positions = <7 8>;
			bindings = <&nav2_double_tap>;
			layers = <
				BASE_LAYER
				KP_MODE_LAYER
				NAV2_LAYER
			>;
		};

		// Комбо J + K (Клавиши 23, 24):
		// Нажатие клавиши BSPC (Backspace).
		// ВАЖНО: nav_1_LAYER и nav_3_LAYER сюда НЕ включены.
		combo_jk_backspace {
			timeout-ms = <50>;
			require-prior-idle-ms = <100>;
			key-positions = <23 24>;
			bindings = <&kp BSPC>;
			layers = <
				BASE_LAYER
				KP_MODE_LAYER
				SYMB_LAYER
				NUMB_LAYER
				NUMB_NOLIGHT_LAYER
				SYMB_NOLIGHT_LAYER
				NUMB_NOLIGHT_COPY_LAYER
				SYMB_ENG_LAYER
                LEFTHAND_LAYER
                LEFTHAND_NOLIGHT_LAYER
				NUMB_ENG_NOLIGHT_LAYER
				SYMB_ENG_NOLIGHT_LAYER
				NUMB_ENG_NOLIGHT_COPY_LAYER
				NAV1_LAYER
				NAV2_LAYER
                NAV2_NOLIGHT_LAYER
				SPEEDTYPE_LAYER
			>;
		};

		// Комбо K + L (Клавиши 24, 25):
		// Нажатие клавиши DEL (Delete).
		// ВАЖНО: nav_1_LAYER и nav_3_LAYER сюда НЕ включены.
		combo_kl_delete {
			timeout-ms = <50>;
			require-prior-idle-ms = <100>;
			key-positions = <24 25>;
			bindings = <&kp DEL>;
			layers = <
				BASE_LAYER
				KP_MODE_LAYER
				SYMB_LAYER
				NUMB_LAYER
				NUMB_NOLIGHT_LAYER
				SYMB_NOLIGHT_LAYER
				NUMB_NOLIGHT_COPY_LAYER
				SYMB_ENG_LAYER
				NUMB_ENG_NOLIGHT_LAYER
                NUMB_ENG_NOLIGHT_COPY_LAYER
				SYMB_ENG_NOLIGHT_LAYER
				NAV1_LAYER
				NAV2_LAYER
                NAV2_NOLIGHT_LAYER
				SPEEDTYPE_LAYER
                LEFTHAND_LAYER
                LEFTHAND_NOLIGHT_LAYER
			>;
		};

		// Комбо D + F (Клавиши 16, 17):
		// Нажатие BSPC (Backspace) на символьных и цифровых слоях.
		combo_lh_bspc {
			timeout-ms = <50>;
			require-prior-idle-ms = <100>;
			key-positions = <16 17>;
			bindings = <&kp BSPC>;
			layers = <
				SYMB_LAYER
				NUMB_LAYER
				NUMB_NOLIGHT_LAYER
				SYMB_NOLIGHT_LAYER
				NUMB_NOLIGHT_COPY_LAYER
				SYMB_ENG_LAYER
				NUMB_ENG_NOLIGHT_LAYER
				SYMB_ENG_NOLIGHT_LAYER
				NAV2_LAYER
                NAV2_NOLIGHT_LAYER
				LEFTHAND_LAYER
				LEFTHAND_NOLIGHT_LAYER
                NUMB_ENG_NOLIGHT_COPY_LAYER
			>;
		};

		// Комбо S + D (Клавиши 15, 16):
		// Нажатие DEL (Delete) на символьных и цифровых слоях.
		combo_lh_del {
			timeout-ms = <50>;
			require-prior-idle-ms = <100>;
			key-positions = <15 16>;
			bindings = <&kp DEL>;
			layers = <
				SYMB_LAYER
				NUMB_LAYER
				NUMB_NOLIGHT_LAYER
				SYMB_NOLIGHT_LAYER
				NUMB_NOLIGHT_COPY_LAYER
				SYMB_ENG_LAYER
				NUMB_ENG_NOLIGHT_LAYER
				SYMB_ENG_NOLIGHT_LAYER
				NUMB_ENG_NOLIGHT_COPY_LAYER
				NAV2_LAYER
                NAV2_NOLIGHT_LAYER
				LEFTHAND_LAYER
				LEFTHAND_NOLIGHT_LAYER
			>;
		};

		// Комбо G + левый большой палец (позиции 18, 43):
		// Второе срабатывание thumb_e_numb_td переключает фиксированный слой NUMB_LAYER.
		combo_left_thumb_e_numb {
			timeout-ms = <200>;
			require-prior-idle-ms = <100>;
			key-positions = <18 43>;
			bindings = <&thumb_e_numb_td>;
			layers = <BASE_LAYER NUMB_LAYER>;
		};

		// Комбо G + левый большой палец в слое 1 (default_2): английские цифры без Alt.
		combo_left_thumb_e_numb_kp {
			timeout-ms = <200>;
			require-prior-idle-ms = <100>;
			key-positions = <18 43>;
			bindings = <&thumb_e_numb_eng_td>;
			layers = <KP_MODE_LAYER NUMB_ENG_NOLIGHT_LAYER>;
		};

		// Комбо H + правый большой палец (позиции 22, 46):
		// Русский persistent-символьный слой SYMB_LAYER, как в старом keymap.
		combo_right_thumb_i_symb_ru {
			timeout-ms = <200>;
			require-prior-idle-ms = <100>;
			key-positions = <22 46>;
			bindings = <&thumb_i_symb_td>;
			layers = <BASE_LAYER SYMB_LAYER>;
		};

		// Комбо H + правый большой палец в Android-режиме:
		// Переключает постоянный английский циановый слой SYMB_ENG_LAYER.
		combo_right_thumb_i_symb_eng {
			timeout-ms = <200>;
			require-prior-idle-ms = <100>;
			key-positions = <22 46>;
			bindings = <&thumb_i_symb_eng_td>;
			layers = <
				KP_MODE_LAYER
				SYMB_ENG_LAYER
			>;
		};

		// Комбо I + O + P + [ (позиции 9,10,11,12):
		// &to BASE_LAYER, затем ручная WS2812-индикация через &ws2812_wdg 0.
		combo_iop_lbkt_reset {
			timeout-ms = <100>;
			require-prior-idle-ms = <250>;
			key-positions = <9 10 11 12>;
			bindings = <&reset_l0_green_flash>;
			layers = <
				BASE_LAYER
				KP_MODE_LAYER
				SYMB_LAYER
				NUMB_LAYER
				SYMB_ENG_LAYER
				NAV2_LAYER
				GAMING1_LAYER
				SPEEDTYPE_LAYER
				LEFTHAND_LAYER
			>;
		};

		// Комбо COMMA + DOT + FSLH + ESC (клавиши 38, 39, 40, 41):
		// Сброс на default_2 + оранжевая вспышка подсветки.
		combo_comma_dot_fslh_esc_reset_kp {
			timeout-ms = <100>;
			require-prior-idle-ms = <250>;
			key-positions = <38 39 40 41>;
			bindings = <&reset_kp_mode_green_flash>;
			layers = <
				BASE_LAYER
				KP_MODE_LAYER
				SYMB_LAYER
				NUMB_LAYER
				SYMB_ENG_LAYER
				NAV2_LAYER
				GAMING1_LAYER
				SPEEDTYPE_LAYER
				LEFTHAND_LAYER
			>;
		};
    };

	// --- РАСКЛАДКИ И СЛОИ (KEYMAP) ---
	keymap {
		compatible = "zmk,keymap";

		// Слой 0: default_1_layer
		default_1_layer {
			display-name = "default_1_layer";
			bindings = <
				&kp TAB      &kp Q             &kp W             &kp E                                   &kp R                                 &t_yo_ht GRAVE T                         &kp UP                &media_ht C_PP Y    &media_ht C_PREV U                      &media_ht C_NEXT I                &media_ht C_STOP O  &kp P                      &lbkt_screenshot 0 LBKT
				&kp LSHIFT   &edit_ht LC(A) A  &edit_ht LC(S) S  &kp D                                   &edit_ht LC(F) F                      &kp G                          &kp LEFT  &kp SPC   &kp RIGHT   &kp H               &kp J                                   &kp K                             &kp L               &semi_fn_ht FN_LAYER SEMI  &mt LSHFT SQT
				&kp LCTRL    &edit_ht LC(Z) Z  &edit_ht LC(X) X  &edit_ht LC(C) C                        &edit_ht LC(V) V                      &b_alt_ht LALT B   &kp C_MUTE            &kp DOWN              &n_alt_ht LALT N    &kp M                                   &kp COMMA                         &kp DOT             &kp FSLH                   &kp ESC
				                                                 &lefthand_ht LEFTHAND_NOLIGHT_LAYER 0   &symb_win_td SYMB_NOLIGHT_LAYER 0     &kp SPACE                                                      &kp ENTER           &thumb_num_sym_fn NUMB_NOLIGHT_LAYER 0  &lang_nav2 NAV2_NOLIGHT_LAYER 0
			>;
			sensor-bindings = <&inc_dec_kp C_VOLUME_UP C_VOLUME_DOWN>;
		};

		// Слой 1: default_2_layer
		default_2_layer {
			display-name = "default_2_layer";
			bindings = <
				&kp TAB       &kp Q             &kp W             &kp E                                   &kp R                                   &t_yo_ht GRAVE T                         &kp UP                &media_ht C_PP Y    &media_ht C_PREV U                          &media_ht C_NEXT I               &media_ht C_STOP O  &kp P                      &lbkt_screenshot 0 LBKT
				&kp LSHIFT    &edit_ht LC(A) A  &edit_ht LC(S) S  &kp D                                   &edit_ht LC(F) F                        &kp G                          &kp LEFT  &kp SPC   &kp RIGHT   &kp H               &kp J                                       &kp K                            &kp L               &semi_fn_ht FN_LAYER SEMI  &mt LSHFT SQT
				&kp LCTRL     &edit_ht LC(Z) Z  &edit_ht LC(X) X  &edit_ht LC(C) C                        &edit_ht LC(V) V                        &b_alt_ht LALT B   &kp C_MUTE            &kp DOWN              &n_alt_ht LALT N    &kp M                                       &kp COMMA                        &kp DOT             &kp FSLH                   &kp ESC
				                                                  &lefthand_ht LEFTHAND_NOLIGHT_LAYER 0   &symb_win_td SYMB_ENG_NOLIGHT_LAYER 0   &kp SPACE                                                      &kp ENTER           &thumb_num_sym_fn NUMB_ENG_NOLIGHT_LAYER 0  &lang_nav2 NAV2_NOLIGHT_LAYER 0
			>;
			sensor-bindings = <&inc_dec_kp C_VOLUME_UP C_VOLUME_DOWN>;
		};

		// Слой 2: SYMB — русские символы через Alt, persistent.
		// Левая крайняя клавиша второго ряда:
		//   hold -> SYMB_NOLIGHT_LAYER, tap  -> /
		symb_layer {
			display-name = "symb_layer";
			bindings = <
				&hash_dollar_ht DLLR HASH                 &rpar_rbrc_ht RBRC RPAR       &lpar_lbrc_ht LBRC LPAR        &astrk_caret_ht CARET ASTRK    &qmark_dqt_ht 0 0       &excl_tilde_ht TILDE EXCL                              &kp UP                 &excl_tilde_ht TILDE EXCL     &qmark_dqt_ht 0 0            &astrk_caret_ht CARET ASTRK  &lpar_lbrc_ht LBRC LPAR      &rpar_rbrc_ht RBRC RPAR       &hash_dollar_ht DLLR HASH
				&slash_to_numb_ht SYMB_NOLIGHT_LAYER 0    &semi_rbrc_ht 0 0             &comma_lbrc_ht LBRC COMMA      &dot_lbkt_ht LBKT DOT          &rbkt_sqt_ht SQT RBKT   &colon_at_ht AT COLON                        &kp LEFT  &kp SPC   &kp RIGHT    &colon_at_ht AT COLON         &rbkt_sqt_ht SQT RBKT        &dot_lbkt_ht LBKT DOT        &comma_lbrc_ht LBRC COMMA    &semi_rbrc_ht 0 0             &slash_to_numb_ht NUMB_NOLIGHT_LAYER 0
				&dqt_pipe_ht PIPE 0                       &percent_amp_ht PRCNT AMPS    &equal_tilde_ht TILDE EQUAL    &plus_gt_ht GT PLUS            &minus_lt_ht LT MINUS   &under_lshft_ht LSHFT UNDER     &trans                 &kp DOWN               &under_lshft_ht LSHFT UNDER   &minus_lt_ht LT MINUS        &plus_gt_ht GT PLUS          &equal_tilde_ht TILDE EQUAL  &percent_amp_ht PRCNT AMPS    &dqt_pipe_ht PIPE 0
				                                                                                                       &trans                         &trans                  &kp SPACE                                                                     &kp ENTER                     &trans                       &trans
			>;
			sensor-bindings = <&inc_dec_kp LC(RIGHT) LC(LEFT)>;
		};

		// Слой 3: NUMB — русские цифры/Numpad, persistent.
		numb_layer {
			display-name = "numb_layer";
			bindings = <
				&kp C_AL_CALCULATOR                         &mul_comma_ht KP_MULTIPLY COMMA   &kp N9  &kp N8  &kp N7  &kp KP_PLUS                                     &msc SCRL_UP                       &kp KP_PLUS    &kp N7  &kp N8  &kp N9  &mul_comma_ht KP_MULTIPLY COMMA   &kp C_AL_CALCULATOR
				&bspc_to_layer_ht SYMB_NOLIGHT_LAYER BSPC   &kp N0                            &kp N6  &kp N5  &kp N4  &kp KP_MINUS                  &msc SCRL_LEFT    &mkp LCLK       &msc SCRL_RIGHT    &kp KP_MINUS   &kp N4  &kp N5  &kp N6  &kp N0                            &kp BSPC
				&div_lshft_ht LSHFT KP_ENTER                &div_dot_ht KP_DIVIDE DOT         &kp N3  &kp N2  &kp N1  &kp KP_EQUAL    &trans                          &msc SCRL_DOWN                     &kp KP_EQUAL   &kp N1  &kp N2  &kp N3  &div_dot_ht KP_DIVIDE DOT         &div_lshft_ht LSHFT KP_ENTER
				                                                                                      &trans  &trans  &kp SPACE                                                                          &kp ENTER      &trans  &trans
			>;
			sensor-bindings = <&inc_dec_kp LC(RIGHT) LC(LEFT)>;
		};

		// Слой 4: NUMB no-light Alt.
		// Крайние клавиши второго ряда по удержанию ведут на SYMB_NOLIGHT_LAYER.
		numbnolight_layer {
			display-name = "numbnolight_layer";
			bindings = <
				&kp C_AL_CALCULATOR                          &mul_comma_ht KP_MULTIPLY COMMA    &kp N9  &kp N8  &kp N7  &kp KP_PLUS                                  &msc SCRL_UP                      &kp KP_PLUS     &kp N7  &kp N8  &kp N9  &mul_comma_ht KP_MULTIPLY COMMA    &kp C_AL_CALCULATOR
				&bspc_to_layer_ht SYMB_NOLIGHT_LAYER BSPC    &kp N0                             &kp N6  &kp N5  &kp N4  &kp KP_MINUS                &msc SCRL_LEFT   &mkp LCLK       &msc SCRL_RIGHT   &kp KP_MINUS    &kp N4  &kp N5  &kp N6  &kp N0                             &bspc_to_layer_ht SYMB_NOLIGHT_LAYER BSPC
				&div_lshft_ht LSHFT KP_ENTER                 &div_dot_ht KP_DIVIDE DOT          &kp N3  &kp N2  &kp N1  &kp KP_EQUAL    &trans                       &msc SCRL_DOWN                    &kp KP_EQUAL    &kp N1  &kp N2  &kp N3  &div_dot_ht KP_DIVIDE DOT          &div_lshft_ht LSHFT KP_ENTER
				                                                                                        &trans  &trans  &kp SPACE                                                                      &kp ENTER       &trans  &trans
			>;
			sensor-bindings = <&inc_dec_kp LC(RIGHT) LC(LEFT)>;
		};

		// Слой 5: SYMB no-light Alt.
		// Крайние клавиши второго ряда по удержанию ведут на NUMB_NOLIGHT_COPY_LAYER.
		symbnolight_layer {
			display-name = "symbnolight_layer";
			bindings = <
				&hash_dollar_ht DLLR HASH                       &rpar_rbrc_ht RBRC RPAR       &lpar_lbrc_ht LBRC LPAR        &astrk_caret_ht CARET ASTRK    &qmark_dqt_ht 0 0       &excl_tilde_ht TILDE EXCL                              &kp UP                 &excl_tilde_ht TILDE EXCL     &qmark_dqt_ht 0 0            &astrk_caret_ht CARET ASTRK  &lpar_lbrc_ht LBRC LPAR      &rpar_rbrc_ht RBRC RPAR       &hash_dollar_ht DLLR HASH
				&slash_to_numb_ht NUMB_NOLIGHT_COPY_LAYER 0     &semi_rbrc_ht 0 0             &comma_lbrc_ht LBRC COMMA      &dot_lbkt_ht LBKT DOT          &rbkt_sqt_ht SQT RBKT   &colon_at_ht AT COLON                        &kp LEFT  &kp SPC   &kp RIGHT    &colon_at_ht AT COLON         &rbkt_sqt_ht SQT RBKT        &dot_lbkt_ht LBKT DOT        &comma_lbrc_ht LBRC COMMA    &semi_rbrc_ht 0 0             &slash_to_numb_ht NUMB_NOLIGHT_COPY_LAYER 0
				&dqt_pipe_ht PIPE 0                             &percent_amp_ht PRCNT AMPS    &equal_tilde_ht TILDE EQUAL    &plus_gt_ht GT PLUS            &minus_lt_ht LT MINUS   &under_lshft_ht LSHFT UNDER     &trans                 &kp DOWN               &under_lshft_ht LSHFT UNDER   &minus_lt_ht LT MINUS        &plus_gt_ht GT PLUS          &equal_tilde_ht TILDE EQUAL  &percent_amp_ht PRCNT AMPS    &dqt_pipe_ht PIPE 0
				                                                                                                             &trans                         &trans                  &kp SPACE                                                                     &kp ENTER                     &trans                       &trans
			>;
			sensor-bindings = <&inc_dec_kp LC(RIGHT) LC(LEFT)>;
		};

		// Слой 6: NUMB no-light copy Alt.
		numbnolightcopy_layer {
			display-name = "numbnolightcopy_layer";
			bindings = <
				&kp C_AL_CALCULATOR             &mul_comma_ht KP_MULTIPLY COMMA  &kp N9  &kp N8  &kp N7  &kp KP_PLUS                                      &msc SCRL_UP                       &kp KP_PLUS    &kp N7  &kp N8  &kp N9  &mul_comma_ht KP_MULTIPLY COMMA   &kp C_AL_CALCULATOR
				&kp BSPC                        &kp N0                           &kp N6  &kp N5  &kp N4  &kp KP_MINUS                   &msc SCRL_LEFT    &mkp LCLK       &msc SCRL_RIGHT    &kp KP_MINUS   &kp N4  &kp N5  &kp N6  &kp N0                            &kp BSPC
				&div_lshft_ht LSHFT KP_ENTER    &div_dot_ht KP_DIVIDE DOT        &kp N3  &kp N2  &kp N1  &kp KP_EQUAL    &trans                           &msc SCRL_DOWN                     &kp KP_EQUAL   &kp N1  &kp N2  &kp N3  &div_dot_ht KP_DIVIDE DOT         &div_lshft_ht LSHFT KP_ENTER
				                                                                         &trans  &trans  &kp SPACE                                                                           &kp ENTER      &trans  &trans
			>;
			sensor-bindings = <&inc_dec_kp LC(RIGHT) LC(LEFT)>;
		};

		// Слой 7: SYMB English persistent без Alt (циан).
		// Левая крайняя клавиша второго ряда: hold -> NUMB_ENG_NOLIGHT_LAYER
		// Правая крайняя клавиша второго ряда:
		// hold -> NUMB_ENG_NOLIGHT_LAYER
		// tap  -> BSLH
		// Alt-code только в hold ° и — (для них нет кейкода без Alt).
		symb_2_layer {
			display-name = "symb_2_layer";
			bindings = <
				&eng_sym_ht LS(N4) LS(N3)                          &eng_sym_ht LS(RBKT) LS(N0)       &eng_sym_ht LS(LBKT) LS(N9)    &eng_sym_ht LS(N6) LS(N8)                   &eng_sym_ht LS(N7) LS(FSLH)                &eng_sym_ht LS(GRAVE) LS(N1)                          &kp UP                 &eng_sym_ht LS(GRAVE) LS(N1)    &eng_sym_ht LS(N7) LS(FSLH)                      &eng_sym_ht LS(N6) LS(N8)             &eng_sym_ht LS(LBKT) LS(N9)       &eng_sym_ht LS(RBKT) LS(N0)    &eng_sym_ht LS(N4) LS(N3)
				&bspc_to_layer_ht NUMB_ENG_NOLIGHT_LAYER FSLH      &eng_sym_ht GRAVE SEMI            &eng_comma_degree_ht 0 COMMA   &eng_sym_ht LBKT DOT                        &eng_sym_ht SQT RBKT                       &eng_sym_ht LS(N2) LS(SEMI)                 &kp LEFT  &kp SPC   &kp RIGHT    &eng_sym_ht LS(N2) LS(SEMI)     &eng_sym_ht SQT RBKT                             &eng_sym_ht LBKT DOT                  &eng_comma_degree_ht 0 COMMA      &eng_sym_ht GRAVE SEMI         &bspc_to_layer_ht NUMB_ENG_NOLIGHT_LAYER FSLH
				&eng_sym_ht LS(BSLH) LS(N5)                        &eng_sym_ht BSLH LS(SQT)          &eng_ht_none_kp 0 EQUAL        &eng_sym_ht LS(DOT) LS(EQUAL)               &eng_sym_ht LS(COMMA) MINUS                &eng_under_emdash_ht 0 UNDER      &none               &kp DOWN               &eng_under_emdash_ht 0 UNDER    &eng_sym_ht LS(COMMA) MINUS                      &eng_sym_ht LS(DOT) LS(EQUAL)         &eng_ht_none_kp 0 EQUAL           &eng_sym_ht BSLH LS(SQT)       &eng_sym_ht LS(BSLH) LS(N5)
				                                                                                                                    &lefthand_ht LEFTHAND_NOLIGHT_LAYER 0       &symb_win_td SYMB_ENG_NOLIGHT_LAYER 0      &kp SPACE                                                                    &kp ENTER                       &thumb_num_sym_fn NUMB_ENG_NOLIGHT_LAYER 0       &lang_nav2 NAV2_NOLIGHT_LAYER 0
			>;
			sensor-bindings = <&inc_dec_kp LC(RIGHT) LC(LEFT)>;
		};

		// Слой 8: NUMB English no-light main.
		// Крайние клавиши второго ряда по удержанию ведут на SYMB_NOLIGHT_LAYER_2.
		numbnolight_2_layer {
			display-name = "numbnolight_2_layer";
			bindings = <
				&kp C_AL_CALCULATOR                             &eng_ht KP_MULTIPLY COMMA   &kp N9  &kp N8  &kp N7  &kp KP_PLUS                                     &msc SCRL_UP                      &kp KP_PLUS     &kp N7  &kp N8  &kp N9  &eng_ht KP_MULTIPLY COMMA   &kp C_AL_CALCULATOR
				&bspc_to_layer_ht SYMB_ENG_NOLIGHT_LAYER BSPC   &kp N0                      &kp N6  &kp N5  &kp N4  &kp KP_MINUS                   &msc SCRL_LEFT   &mkp LCLK       &msc SCRL_RIGHT   &kp KP_MINUS    &kp N4  &kp N5  &kp N6  &kp N0                      &bspc_to_layer_ht SYMB_ENG_NOLIGHT_LAYER BSPC
				&div_lshft_ht LSHFT KP_ENTER                    &eng_ht KP_DIVIDE DOT       &kp N3  &kp N2  &kp N1  &kp KP_EQUAL    &trans                          &msc SCRL_DOWN                    &kp KP_EQUAL    &kp N1  &kp N2  &kp N3  &eng_ht KP_DIVIDE DOT       &div_lshft_ht LSHFT KP_ENTER
				                                                                                    &trans  &trans  &kp SPACE                                                                         &kp ENTER       &trans  &trans
			>;
			sensor-bindings = <&inc_dec_kp LC(RIGHT) LC(LEFT)>;
		};

		// Слой 9: SYMB English no-light main.
		// Крайние клавиши второго ряда по удержанию ведут на NUMB_ENG_NOLIGHT_COPY_LAYER.
		// Правый большой палец по удержанию тоже ведёт в цифры, чтобы из английского символического слоя был переход в цифры.
		// Alt-code только в hold ° и — (для них нет кейкода без Alt).
		symbnolight_2_layer {
			display-name = "symbnolight_2_layer";
			bindings = <
				&eng_sym_ht LS(N4) LS(N3)                             &eng_sym_ht LS(RBKT) LS(N0)       &eng_sym_ht LS(LBKT) LS(N9)    &eng_sym_ht LS(N6) LS(N8)                &eng_sym_ht LS(N7) LS(FSLH)                &eng_sym_ht LS(GRAVE) LS(N1)                       &kp UP                 &eng_sym_ht LS(GRAVE) LS(N1)    &eng_sym_ht LS(N7) LS(FSLH)                        &eng_sym_ht LS(N6) LS(N8)             &eng_sym_ht LS(LBKT) LS(N9)     &eng_sym_ht LS(RBKT) LS(N0)    &eng_sym_ht LS(N4) LS(N3)
				&bspc_to_layer_ht NUMB_ENG_NOLIGHT_COPY_LAYER FSLH    &eng_sym_ht GRAVE SEMI            &eng_comma_degree_ht 0 COMMA   &eng_sym_ht LBKT DOT                     &eng_sym_ht SQT RBKT                       &eng_sym_ht LS(N2) LS(SEMI)              &kp LEFT  &kp SPC   &kp RIGHT    &eng_sym_ht LS(N2) LS(SEMI)     &eng_sym_ht SQT RBKT                               &eng_sym_ht LBKT DOT                  &eng_comma_degree_ht 0 COMMA    &eng_sym_ht GRAVE SEMI         &bspc_to_layer_ht NUMB_ENG_NOLIGHT_COPY_LAYER FSLH
				&eng_sym_ht LS(BSLH) LS(N5)                           &eng_sym_ht BSLH LS(SQT)          &eng_ht_none_kp 0 EQUAL        &eng_sym_ht LS(DOT) LS(EQUAL)            &eng_sym_ht LS(COMMA) MINUS                &eng_under_emdash_ht 0 UNDER   &none               &kp DOWN               &eng_under_emdash_ht 0 UNDER    &eng_sym_ht LS(COMMA) MINUS                        &eng_sym_ht LS(DOT) LS(EQUAL)         &eng_ht_none_kp 0 EQUAL         &eng_sym_ht BSLH LS(SQT)       &eng_sym_ht LS(BSLH) LS(N5)
				                                                                                                                       &lefthand_ht LEFTHAND_NOLIGHT_LAYER 0    &symb_win_td SYMB_ENG_NOLIGHT_LAYER 0      &kp SPACE                                                                 &kp ENTER                       &thumb_num_sym_fn NUMB_ENG_NOLIGHT_COPY_LAYER 0    &lang_nav2 NAV2_NOLIGHT_LAYER 0
			>;
			sensor-bindings = <&inc_dec_kp LC(RIGHT) LC(LEFT)>;
		};

		// Слой 10: FN — F1-F12 и управление мышью.
		fn_layer {
			display-name = "fn_layer";
			bindings = <
				&kp ESC       &none   &none    &kp F9    &kp F5        &mkp MB5                                          &mmv MOVE_UP                       &kp F10    &kp F7  &kp F8     &kp F9  &none  &none
				&kp LSHIFT    &none   &none    &kp F1    &kp F11       &mkp MB4                        &mmv MOVE_LEFT    &mkp LCLK       &mmv MOVE_RIGHT    &kp F11    &kp F4  &kp F5     &kp F6  &none  &none
				&kp LCTRL     &none   &none    &none     &none         &kp C_AL_CALCULATOR  &none                        &mmv MOVE_DOWN                     &kp F12    &kp F1  &kp F2     &kp F3  &none  &none
				                               &kp RALT  &kp LEFT_GUI  &kp SPACE                                                                            &kp ENTER  &none   &lang_only
			>;
			sensor-bindings = <&inc_dec_kp LC(RIGHT) LC(LEFT)>;
		};

		// Слой 11: SERVICE.
		// Оставлен как в твоём варианте: &symb_eng_swap_toggle на месте.
		service_layer {
			display-name = "service_layer";
			bindings = <
				&slpall               &symb_eng_swap_toggle       &ws2812_wdg 8             &repeat_ws2812_brightness_down   &repeat_ws2812_brightness_up    &studio_unlock                      &none               &bt BT_CLR        &slpsrc           &bt BT_SEL 0        &bt BT_SEL 1       &bt BT_SEL 2     &bt BT_SEL 3
				&rgb_timer_custom 0   &repeat_rgb_timeout_down    &repeat_rgb_timeout_up    &ws2812_wdg 1                    &ws2812_wdg 2                   &out OUT_BLE                &none   &none   &none       &kp C_BRI_DN      &kp C_BRI_UP      &repeat_rgb_hud     &repeat_rgb_hui    &repeat_rgb_sad  &repeat_rgb_sai
				&bt BT_CLR_ALL        &kp LA(F4)                  &kp LG(LC(LEFT))          &kp LG(LC(RIGHT))                &ws2812_wdg 10                  &out OUT_USB     &none              &none               &repeat_rgb_efr   &repeat_rgb_eff   &repeat_rgb_spd     &repeat_rgb_spi    &repeat_rgb_brd  &repeat_rgb_bri
				                                                                            &none                            &none                           &none                                                   &rgb_ug RGB_ON    &none             &rgb_ug RGB_OFF
			>;
			sensor-bindings = <&inc_dec_kp C_VOLUME_UP C_VOLUME_DOWN>;
		};

		// Слой 12: nav_1
		nav_1_layer {
			display-name = "nav_1_layer";
			bindings = <
				&kp LC(LA(DEL))  &kp PSCRN         &kp LG(ESC)        &none  &none  &none                               &mmv MOVE_UP                       &kp HOME           &mkp LCLK          &kp UP      &mkp RCLK            &macro_comma_uni   &kp PG_UP
				&kp LSHIFT       &kp PAUSE_BREAK   &kp LG(KP_PLUS)    &none  &none  &none               &mmv MOVE_LEFT  &mkp LCLK      &mmv MOVE_RIGHT     &msc MOVE_X(-150)  &kp LEFT           &kp DOWN    &kp RIGHT            &msc MOVE_X(150)   &kp BSPC
				&kp LCTRL        &kp INS           &kp LG(KP_MINUS)   &none  &none  &none       &none                   &mmv MOVE_DOWN                     &kp END            &msc MOVE_Y(-150)  &mkp MCLK   &msc MOVE_Y(150)     &macro_qmark_uni   &kp PG_DN
				                                                      &none  &none  &kp SPACE                                                              &kp ENTER          &none              &lang_only
			>;
			sensor-bindings = <&inc_dec_kp LC(RIGHT) LC(LEFT)>;
		};

		// Слой 13: nav_2
		nav_2_layer {
			display-name = "nav_2_layer";
			bindings = <
				&none   &none   &none   &none   &none   &none                        &none               &none       &kp HOME  &kp PG_UP     &kp ESC    &kp DEL   &kp BSPC
				&none   &none   &none   &none   &none   &none                &none   &none   &none       &none       &kp END   &kp PG_DN     &kp ENTER  &kp UP    &kp SPC
				&none   &none   &none   &none   &none   &none      &none             &none               &none       &none     &kp LSHFT     &kp LEFT   &kp DOWN  &kp RIGHT
				                        &none   &none   &kp SPACE                                        &kp ENTER   &none     &lang_only
			>;
			sensor-bindings = <&inc_dec_kp C_VOLUME_UP C_VOLUME_DOWN>;
		};

		// Слой 14: NAV2 no-light.
		nav2nolight_layer {
			display-name = "nav2nolight_layer";
			bindings = <
				&none   &none   &none   &none   &none   &none                        &none               &none       &kp HOME  &kp PG_UP  &kp ESC    &kp DEL   &kp BSPC
				&none   &none   &none   &none   &none   &none                &none   &none   &none       &none       &kp END   &kp PG_DN  &kp ENTER  &kp UP    &kp SPC
				&none   &none   &none   &none   &none   &none      &none             &none               &none       &none     &kp LSHFT  &kp LEFT   &kp DOWN  &kp RIGHT
				                        &none   &none   &kp SPACE                                        &kp ENTER   &none     &none
			>;
			sensor-bindings = <&inc_dec_kp LC(RIGHT) LC(LEFT)>;
		};

		// Слой 15: nav_3
		nav_3_layer {
			display-name = "nav_3_layer";
			bindings = <
				&kp LC(LA(DEL))  &kp PSCRN         &kp LG(ESC)        &none  &none  &none                            &kp UP                   &kp HOME           &mkp LCLK            &mmv MOVE_UP    &mkp RCLK          &macro_comma_uni   &kp PG_UP
				&kp LSHIFT       &kp PAUSE_BREAK   &kp LG(KP_PLUS)    &none  &none  &none                  &kp LEFT  &kp ENTER  &kp RIGHT     &msc MOVE_X(-150)  &mmv MOVE_LEFT       &mmv MOVE_DOWN  &mmv MOVE_RIGHT    &msc MOVE_X(150)   &kp BSPC
				&kp LCTRL        &kp INS           &kp LG(KP_MINUS)   &none  &none  &none     &kp C_MUTE             &kp DOWN                 &kp END            &msc MOVE_Y(-150)    &mkp MCLK       &msc MOVE_Y(150)   &macro_dot_uni     &kp PG_DN
				                                                      &none  &none  &kp SPACE                                                 &kp ENTER          &none                &lang_only
			>;
			sensor-bindings = <&inc_dec_kp LC(RIGHT) LC(LEFT)>;
		};

		// Слой 16: gaming_1
		gaming_1_layer {
			display-name = "gaming1_layer";
			bindings = <
				&kp TAB    &kp Q  &kp W  &kp E                                &kp R                             &kp T                             &kp UP                  &kp Y      &kp U                &kp I        &kp O     &kp P     &kp BSPC
				&kp LSHFT  &kp A  &kp S  &kp D                                &kp F                             &kp G                   &kp LEFT  &kp ENTER  &kp RIGHT    &kp H      &kp J                &kp K        &kp L     &kp SEMI  &kp LSHFT
				&kp LCTRL  &kp Z  &kp X  &kp C                                &kp V                             &kp B      &kp C_MUTE             &kp DOWN                &kp N      &kp M                &kp COMMA    &kp DOT   &kp FSLH  &kp ESC
				                         &gaming_mo9_alt GAMING3_LAYER 0      &gaming_mo2_win GAMING2_LAYER 0   &kp SPACE                                                 &kp ENTER  &gaming1_num_ht 0 0  &lang_only
			>;
			sensor-bindings = <&inc_dec_kp C_VOLUME_UP C_VOLUME_DOWN>;
		};

		// Слой 17: gaming_2
		gaming_2_layer {
			display-name = "gaming2_layer";
			bindings = <
				&kp ESC                                           &kp N1   &none    &kp N2   &kp N3  &none                                &kp UP                 &kp F10       &kp F7                &kp F8      &kp F9  &none    &kp BSPC
				&gaming_shft_mo21 LEFTHAND_NOLIGHT_LAYER LSHFT    &kp N4   &none    &kp N5   &kp N6  &kp N0                    &kp LEFT   &kp ENTER  &kp RIGHT   &kp F11       &kp F4                &kp F5      &kp F6  &none    &kp LSHFT
				&kp LCTRL                                         &kp N7   &none    &kp N8   &kp N9  &none       &kp C_MUTE               &kp DOWN               &kp F12       &kp F1                &kp F2      &kp F3  &none    &kp ESC
				                                                                    &none    &none   &kp SPACE                                                   &kp ENTER     &gaming2_num_ht 0 0   &lang_only
			>;
			sensor-bindings = <&inc_dec_kp LC(RIGHT) LC(LEFT)>;
		};

		// Слой 18: gaming_3
		gaming_3_layer {
			display-name = "gaming3_layer";
			bindings = <
				&kp ESC    &kp Y  &kp U  &kp I   &kp O      &kp P                           &kp UP                 &kp F10       &kp F7                &kp F8      &kp F9  &none    &kp BSPC
				&kp LSHFT  &kp H  &kp J  &kp K   &kp L      &none                &kp LEFT   &kp ENTER  &kp RIGHT   &kp F11       &kp F4                &kp F5      &kp F6  &none    &kp LSHFT
				&kp LCTRL  &kp M  &none  &kp N   &kp COMMA  &kp DOT   &kp C_MUTE            &kp DOWN               &kp F12       &kp F1                &kp F2      &kp F3  &none    &kp ESC
				                         &none   &none      &kp SPACE                                              &kp ENTER     &gaming3_num_ht 0 0   &lang_only
			>;
			sensor-bindings = <&inc_dec_kp LC(RIGHT) LC(LEFT)>;
		};

		// Слой 19: SPEEDTYPE.
		speedtype_layer {
			display-name = "speedtype_layer";
			bindings = <
				&kp TAB    &kp Q  &kp W  &kp E      &kp R                    &t_yo_ht GRAVE T                           &kp UP                 &kp Y      &kp U              &kp I                            &kp O     &kp P     &kp LBKT
				&kp LSHFT  &kp A  &kp S  &kp D      &kp F                    &kp G                            &kp LEFT  &kp ENTER  &kp RIGHT   &kp H      &kp J              &kp K                            &kp L     &kp SEMI  &kp SQT
				&kp LCTRL  &kp Z  &kp X  &kp C      &kp V                    &kp B             &kp C_MUTE               &kp DOWN               &kp N      &kp M              &kp COMMA                        &kp DOT   &kp FSLH  &kp ESC
				                         &kp RALT   &speed_symb_win_ht 0 0   &kp SPACE                                                         &kp ENTER  &speed_num_ht 0 0  &lang_nav2 NAV2_NOLIGHT_LAYER 0
			>;
			sensor-bindings = <&inc_dec_kp C_VOLUME_UP C_VOLUME_DOWN>;
		};

		// Слой 20: LEFTHAND.
		lefthand_layer {
			display-name = "lefthand_layer";
			bindings = <
				&kp TAB     &kp HOME        &kp ENTER         &kp UP       &kp SPC            &mkp MB5                             &kp UP                  &kp LG(SEMI)       &kp LG(UP)             &kp LG(DOWN)     &kp LG(C)      &kp LG(TAB)        &kp KP_NUM
				&kp LSHFT   &kp END         &kp LEFT          &kp DOWN     &kp RIGHT          &mkp MB4                   &kp LEFT  &kp ENTER  &kp RIGHT    &kp C_AC_SEARCH    &kp F2                 &kp LC(LS(N))    &kp LC(P)      &kp LC(LS(ESC))    &kp SLCK
				&kp LCTRL   &kp LC(LS(T))   &kp LC(LS(TAB))   &kp LC(R)    &kp LC(TAB)        &kp LC(W)    &kp C_MUTE              &kp DOWN                &kp LG(E)          &kp LG(LEFT)           &kp LG(RIGHT)    &kp LG(H)      &kp LG(L)          &kp LG(D)
				                                              &none        &none              &kp SPACE                                                    &kp ENTER          &lefthand_num_ht 0 0   &lang_only
			>;
			sensor-bindings = <&inc_dec_kp C_VOLUME_UP C_VOLUME_DOWN>;
		};

		// Слой 21: LEFTHAND no-light.
		lefthandnolight_layer {
			display-name = "lefthandnolight_layer";
			bindings = <
				&alt_tab     &kp HOME       &kp ENTER         &kp UP       &kp SPC      &mkp MB5                             &kp UP                  &kp LG(SEMI)       &kp LG(UP)                     &kp LG(DOWN)     &kp LG(C)      &kp LG(TAB)        &kp KP_NUM
				&kp LSHFT    &kp END        &kp LEFT          &kp DOWN     &kp RIGHT    &mkp MB4                   &kp LEFT  &kp ENTER  &kp RIGHT    &kp C_AC_SEARCH    &kp F2                         &kp LC(LS(N))    &kp LC(P)      &kp LC(LS(ESC))    &kp SLCK
				&kp LCTRL    &kp LC(LS(T))  &kp LC(LS(TAB))   &kp LC(R)    &kp LC(TAB)  &kp LC(W)    &kp C_MUTE              &kp DOWN                &kp LG(E)          &kp LG(LEFT)                   &kp LG(RIGHT)    &kp LG(H)      &kp LG(L)          &kp LG(D)
				                                              &none        &none        &kp SPACE                                                    &kp ENTER          &lefthand_nolight_num_ht 0 0   &lang_only
			>;
			sensor-bindings = <&inc_dec_kp LC(RIGHT) LC(LEFT)>;
		};

		// Слой 22: NUMB English no-light copy.
		// Нужен, чтобы из SYMB_ENG_NOLIGHT_LAYER (9) работал hold на цифры.
		// Этот слой намеренно самый высокий среди English no-light.
		// Обратный hold из этого слоя в символы не делается, потому что символьные слои ниже и не переопределят активный слой 22.
		numbnolight_copy_2_layer {
			display-name = "numbnolight_copy_2_layer";
			bindings = <
				&kp C_AL_CALCULATOR               &eng_ht KP_MULTIPLY COMMA    &kp N9  &kp N8    &kp N7  &kp KP_PLUS                                 &msc SCRL_UP                      &kp KP_PLUS     &kp N7  &kp N8     &kp N9  &eng_ht KP_MULTIPLY COMMA   &kp C_AL_CALCULATOR
				&kp BSPC                          &kp N0                       &kp N6  &kp N5    &kp N4  &kp KP_MINUS               &msc SCRL_LEFT   &mkp LCLK       &msc SCRL_RIGHT   &kp KP_MINUS    &kp N4  &kp N5     &kp N6  &kp N0                      &kp BSPC
				&div_lshft_ht LSHFT KP_ENTER      &eng_ht KP_DIVIDE DOT        &kp N3  &kp N2    &kp N1  &kp KP_EQUAL    &trans                      &msc SCRL_DOWN                    &kp KP_EQUAL    &kp N1  &kp N2     &kp N3  &eng_ht KP_DIVIDE DOT       &div_lshft_ht LSHFT KP_ENTER
				                                                                       &kp RALT  &trans  &kp SPACE                                                                     &kp ENTER       &trans  &lang_only
			>;
			sensor-bindings = <&inc_dec_kp LC(RIGHT) LC(LEFT)>;
		};
	};
};
